AUTOSAR XML (schema 4-3-0)
package /MICROSAR/Dcm_swc
  5 x mode declaration group, all with category=EXPLICIT_ORDER:
    DcmControlDtcSetting: initial-mode=ENABLEDTCSETTING, on-transition-value=2
      mode ENABLEDTCSETTING: value=0
      mode DISABLEDTCSETTING: value=1
    DcmEcuReset: initial-mode=NONE, on-transition-value=7
      7 x mode:
        NONE: value=0
        HARD: value=1
        KEYONOFF: value=2
        SOFT: value=3
        JUMPTOBOOTLOADER: value=4
        JUMPTOSYSSUPPLIERBOOTLOADER: value=5
        EXECUTE: value=6
    DcmCommunicationControl: initial-mode=DCM_ENABLE_RX_TX_NORM, on-transition-value=12
      12 x mode:
        DCM_ENABLE_RX_TX_NORM: value=0
        DCM_ENABLE_RX_DISABLE_TX_NORM: value=1
        DCM_DISABLE_RX_ENABLE_TX_NORM: value=2
        DCM_DISABLE_RX_TX_NORMAL: value=3
        DCM_ENABLE_RX_TX_NM: value=4
        DCM_ENABLE_RX_DISABLE_TX_NM: value=5
        DCM_DISABLE_RX_ENABLE_TX_NM: value=6
        DCM_DISABLE_RX_TX_NM: value=7
        DCM_ENABLE_RX_TX_NORM_NM: value=8
        DCM_ENABLE_RX_DISABLE_TX_NORM_NM: value=9
        DCM_DISABLE_RX_ENABLE_TX_NORM_NM: value=10
        DCM_DISABLE_RX_TX_NORM_NM: value=11
    DcmResponseOnEvent: initial-mode=EVENT_CLEARED, on-transition-value=3
      mode EVENT_STARTED: value=0
      mode EVENT_STOPPED: value=1
      mode EVENT_CLEARED: value=2
    DcmDiagnosticSessionControl: initial-mode=DEFAULT_SESSION, on-transition-value=255
      9 x mode:
        DEFAULT_SESSION: value=1
        PROGRAMMING_SESSION: value=2
        EXTENDED_SESSION: value=3
        CODING_SESSION: value=65
        RSU_SESSION: value=68
        DEVELOPMENT_SESSION: value=79
        GarageMode: value=95
        SYSTEM_SUPPLIER_SPECIFIC_61: value=97
        DcmDspSessionRow_NXTRMFG: value=126
  data type mapping set DcmMappingSet  # Contains mapping for ModeDeclarationGroups which are provided by Dcm.
    mode-request-type-maps:
      implementation-data-type=Dcm_ControlDtcSettingType, mode-group=DcmControlDtcSetting
      implementation-data-type=Dcm_EcuResetType, mode-group=DcmEcuReset
      implementation-data-type=Dcm_DiagnosticSessionControlType, mode-group=DcmDiagnosticSessionControl
      implementation-data-type=Dcm_CommunicationModeType, mode-group=DcmCommunicationControl
      implementation-data-type=Dcm_ResponseOnEventType, mode-group=DcmResponseOnEvent
package /MICROSAR/Dcm_swc/DataTypes
  38 x impl type:
    Dcm_ConfirmationStatusType: compu {0=DCM_RES_POS_OK, 1=DCM_RES_POS_NOT_OK, 2=DCM_RES_NEG_OK, 3=DCM_RES_NEG_NOT_OK}, implementation-data-type=uint8
    Dcm_OpStatusType: compu {0=DCM_INITIAL, 1=DCM_PENDING, 2=DCM_CANCEL, 3=DCM_FORCE_RCRRP_OK, 64=DCM_FORCE_RCRRP_NOT_OK}, implementation-data-type=uint8
    Dcm_NegativeResponseCodeType: compu {0=DCM_E_POSITIVERESPONSE, 16=DCM_E_GENERALREJECT, 17=DCM_E_SERVICENOTSUPPORTED, 18=DCM_E_SUBFUNCTIONNOTSUPPORTED, 19=DCM_E_INCORRECTMESSAGELENGTHORINVALIDFORMAT, 20=DCM_E_RESPONSETOOLONG, 33=DCM_E_BUSYREPEATREQUEST, 34=DCM_E_CONDITIONSNOTCORRECT, 36=DCM_E_REQUESTSEQUENCEERROR, 37=DCM_E_NORESPONSEFROMSUBNETCOMPONENT, 38=DCM_E_FAILUREPREVENTSEXECUTIONOFREQUESTEDACTION, 49=DCM_E_REQUESTOUTOFRANGE, 51=DCM_E_SECURITYACCESSDENIED, 53=DCM_E_INVALIDKEY, 54=DCM_E_EXCEEDNUMBEROFATTEMPTS, 55=DCM_E_REQUIREDTIMEDELAYNOTEXPIRED, 112=DCM_E_UPLOADDOWNLOADNOTACCEPTED, 113=DCM_E_TRANSFERDATASUSPENDED, 114=DCM_E_GENERALPROGRAMMINGFAILURE, 115=DCM_E_WRONGBLOCKSEQUENCECOUNTER, 120=DCM_E_REQUESTCORRECTLYRECEIVEDRESPONSEPENDING, 126=DCM_E_SUBFUNCTIONNOTSUPPORTEDINACTIVESESSION, 127=DCM_E_SERVICENOTSUPPORTEDINACTIVESESSION, 129=DCM_E_RPMTOOHIGH, 130=DCM_E_RPMTOOLOW, 131=DCM_E_ENGINEISRUNNING, 132=DCM_E_ENGINEISNOTRUNNING, 133=DCM_E_ENGINERUNTIMETOOLOW, 134=DCM_E_TEMPERATURETOOHIGH, 135=DCM_E_TEMPERATURETOOLOW, 136=DCM_E_VEHICLESPEEDTOOHIGH, 137=DCM_E_VEHICLESPEEDTOOLOW, 138=DCM_E_THROTTLE_PEDALTOOHIGH, 139=DCM_E_THROTTLE_PEDALTOOLOW, 140=DCM_E_TRANSMISSIONRANGENOTINNEUTRAL, 141=DCM_E_TRANSMISSIONRANGENOTINGEAR, 143=DCM_E_BRAKESWITCH_NOTCLOSED, 144=DCM_E_SHIFTERLEVERNOTINPARK, 145=DCM_E_TORQUECONVERTERCLUTCHLOCKED, 146=DCM_E_VOLTAGETOOHIGH, 147=DCM_E_VOLTAGETOOLOW, 240..249=DCM_E_VMSCNC_0..DCM_E_VMSCNC_9, 250=DCM_E_VMSCNC_A, 251=DCM_E_VMSCNC_B, 252=DCM_E_VMSCNC_C, 253=DCM_E_VMSCNC_D, 254=DCM_E_VMSCNC_E}, implementation-data-type=uint8
    Dcm_ProtocolType: compu {0=DCM_OBD_ON_CAN, 1=DCM_OBD_ON_FLEXRAY, 2=DCM_OBD_ON_IP, 3=DCM_UDS_ON_CAN, 4=DCM_UDS_ON_FLEXRAY, 5=DCM_UDS_ON_IP, 12=DCM_NO_ACTIVE_PROTOCOL, 240..254=DCM_SUPPLIER_1..DCM_SUPPLIER_15}, implementation-data-type=uint8
    Dcm_RequestKindType: compu {0=DCM_REQ_KIND_NONE, 1=DCM_REQ_KIND_EXTERNAL, 2=DCM_REQ_KIND_ROE}, implementation-data-type=uint8
    Dcm_SecLevelType: compu {0=DCM_SEC_LEV_LOCKED, 1=DCM_SEC_LEV_L1}, implementation-data-type=uint8
    Dcm_SesCtrlType: compu {1=DCM_DEFAULT_SESSION, 2=DCM_PROGRAMMING_SESSION, 3=DCM_EXTENDED_DIAGNOSTIC_SESSION, 65=DCM_CODING_SESSION, 68=DCM_RSU_SESSION, 79=DCM_DEVELOPMENT_SESSION, 95=DCM_GarageMode, 97=DCM_SYSTEM_SUPPLIER_SPECIFIC_61, 126=DCM_DcmDspSessionRow_NXTRMFG}, implementation-data-type=uint8
    Dem_DTCFormatType: compu {0=DEM_DTC_FORMAT_OBD, 1=DEM_DTC_FORMAT_UDS, 2=DEM_DTC_FORMAT_J1939}, implementation-data-type=uint8
    Dem_DTCKindType: compu {1=DEM_DTC_KIND_ALL_DTCS, 2=DEM_DTC_KIND_EMISSION_REL_DTCS}, implementation-data-type=uint8
    Dem_DTCGroupType: range raw 0..16777215, implementation-data-type=uint32
    Dem_DTCOriginType: compu {1=DEM_DTC_ORIGIN_PRIMARY_MEMORY, 2=DEM_DTC_ORIGIN_MIRROR_MEMORY, 3=DEM_DTC_ORIGIN_PERMANENT_MEMORY, 4=DEM_DTC_ORIGIN_SECONDARY_MEMORY}, implementation-data-type=uint8
    Dcm_ControlDtcSettingType: compu {0=DCM_ENUM_ENABLEDTCSETTING, 1=DCM_ENUM_DISABLEDTCSETTING}, implementation-data-type=uint8
    Dcm_EcuResetType: compu {0=DCM_ENUM_NONE, 1=DCM_ENUM_HARD, 2=DCM_ENUM_KEYONOFF, 3=DCM_ENUM_SOFT, 4=DCM_ENUM_JUMPTOBOOTLOADER, 5=DCM_ENUM_JUMPTOSYSSUPPLIERBOOTLOADER, 6=DCM_ENUM_EXECUTE}, implementation-data-type=uint8
    Dcm_CommunicationModeType: compu {0=DCM_ENABLE_RX_TX_NORM, 1=DCM_ENABLE_RX_DISABLE_TX_NORM, 2=DCM_DISABLE_RX_ENABLE_TX_NORM, 3=DCM_DISABLE_RX_TX_NORMAL, 4=DCM_ENABLE_RX_TX_NM, 5=DCM_ENABLE_RX_DISABLE_TX_NM, 6=DCM_DISABLE_RX_ENABLE_TX_NM, 7=DCM_DISABLE_RX_TX_NM, 8=DCM_ENABLE_RX_TX_NORM_NM, 9=DCM_ENABLE_RX_DISABLE_TX_NORM_NM, 10=DCM_DISABLE_RX_ENABLE_TX_NORM_NM, 11=DCM_DISABLE_RX_TX_NORM_NM}, implementation-data-type=uint8
    Dcm_ResponseOnEventType: compu {0=DCM_ENUM_EVENT_STARTED, 1=DCM_ENUM_EVENT_STOPPED, 2=DCM_ENUM_EVENT_CLEARED}, implementation-data-type=uint8
    Dcm_Data4ByteType: category=ARRAY, sw-calibration-access=READ-ONLY
      element Dcm_Data4ByteTypeElement: array-size=4, array-size-semantics=FIXED-SIZE, implementation-data-type=uint8
    Dcm_Data8ByteType: category=ARRAY, sw-calibration-access=READ-ONLY
      element Dcm_Data8ByteTypeElement: array-size=8, array-size-semantics=FIXED-SIZE, implementation-data-type=uint8
    Dcm_Data132ByteType: category=ARRAY, sw-calibration-access=READ-ONLY
      element Dcm_Data132ByteTypeElement: array-size=132, array-size-semantics=FIXED-SIZE, implementation-data-type=uint8
    Dcm_Data256ByteType: category=ARRAY, sw-calibration-access=READ-ONLY
      element Dcm_Data256ByteTypeElement: array-size=256, array-size-semantics=FIXED-SIZE, implementation-data-type=uint8
    Dcm_Data1024ByteType: category=ARRAY, sw-calibration-access=READ-ONLY
      element Dcm_Data1024ByteTypeElement: array-size=1024, array-size-semantics=FIXED-SIZE, implementation-data-type=uint8
    Dcm_Data6ByteType: category=ARRAY, sw-calibration-access=READ-ONLY
      element Dcm_Data6ByteTypeElement: array-size=6, array-size-semantics=FIXED-SIZE, implementation-data-type=uint8
    Dcm_Data18ByteType: category=ARRAY, sw-calibration-access=READ-ONLY
      element Dcm_Data18ByteTypeElement: array-size=18, array-size-semantics=FIXED-SIZE, implementation-data-type=uint8
    Dcm_Data2ByteType: category=ARRAY, sw-calibration-access=READ-ONLY
      element Dcm_Data2ByteTypeElement: array-size=2, array-size-semantics=FIXED-SIZE, implementation-data-type=uint8
    Dcm_Data57ByteType: category=ARRAY, sw-calibration-access=READ-ONLY
      element Dcm_Data57ByteTypeElement: array-size=57, array-size-semantics=FIXED-SIZE, implementation-data-type=uint8
    Dcm_Data17ByteType: category=ARRAY, sw-calibration-access=READ-ONLY
      element Dcm_Data17ByteTypeElement: array-size=17, array-size-semantics=FIXED-SIZE, implementation-data-type=uint8
    Dcm_Data1ByteType: category=ARRAY, sw-calibration-access=READ-ONLY
      element Dcm_Data1ByteTypeElement: array-size=1, array-size-semantics=FIXED-SIZE, implementation-data-type=uint8
    Dcm_Data12ByteType: category=ARRAY, sw-calibration-access=READ-ONLY
      element Dcm_Data12ByteTypeElement: array-size=12, array-size-semantics=FIXED-SIZE, implementation-data-type=uint8
    Dcm_Data3ByteType: category=ARRAY, sw-calibration-access=READ-ONLY
      element Dcm_Data3ByteTypeElement: array-size=3, array-size-semantics=FIXED-SIZE, implementation-data-type=uint8
    Dcm_Data20ByteType: category=ARRAY, sw-calibration-access=READ-ONLY
      element Dcm_Data20ByteTypeElement: array-size=20, array-size-semantics=FIXED-SIZE, implementation-data-type=uint8
    Dcm_Data15ByteType: category=ARRAY, sw-calibration-access=READ-ONLY
      element Dcm_Data15ByteTypeElement: array-size=15, array-size-semantics=FIXED-SIZE, implementation-data-type=uint8
    Dcm_Data7ByteType: category=ARRAY, sw-calibration-access=READ-ONLY
      element Dcm_Data7ByteTypeElement: array-size=7, array-size-semantics=FIXED-SIZE, implementation-data-type=uint8
    Dcm_Data10ByteType: category=ARRAY, sw-calibration-access=READ-ONLY
      element Dcm_Data10ByteTypeElement: array-size=10, array-size-semantics=FIXED-SIZE, implementation-data-type=uint8
    Dcm_Data100ByteType: category=ARRAY, sw-calibration-access=READ-ONLY
      element Dcm_Data100ByteTypeElement: array-size=100, array-size-semantics=FIXED-SIZE, implementation-data-type=uint8
    Dcm_Data8195ByteType: category=ARRAY, sw-calibration-access=READ-ONLY
      element Dcm_Data8195ByteTypeElement: array-size=8195, array-size-semantics=FIXED-SIZE, implementation-data-type=uint8
    Dcm_Data9ByteType: category=ARRAY, sw-calibration-access=READ-ONLY
      element Dcm_Data9ByteTypeElement: array-size=9, array-size-semantics=FIXED-SIZE, implementation-data-type=uint8
    Dcm_DiagnosticSessionControlType: compu {1=DCM_ENUM_DEFAULT_SESSION, 2=DCM_ENUM_PROGRAMMING_SESSION, 3=DCM_ENUM_EXTENDED_SESSION, 65=DCM_ENUM_CODING_SESSION, 68=DCM_ENUM_RSU_SESSION, 79=DCM_ENUM_DEVELOPMENT_SESSION, 95=DCM_ENUM_GarageMode, 97=DCM_ENUM_SYSTEM_SUPPLIER_SPECIFIC_61, 126=DCM_ENUM_DcmDspSessionRow_NXTRMFG}, implementation-data-type=uint8
    Dcm_Data40ByteType: category=ARRAY, sw-calibration-access=READ-ONLY
      element Dcm_Data40ByteTypeElement: array-size=40, array-size-semantics=FIXED-SIZE, implementation-data-type=uint8
    Dcm_Data48ByteType: category=ARRAY, sw-calibration-access=READ-ONLY
      element Dcm_Data48ByteTypeElement: array-size=48, array-size-semantics=FIXED-SIZE, implementation-data-type=uint8
package /MICROSAR/Dcm_swc/Interfaces
  5 x mode switch interface, all with is-service=true, service-kind=DIAGNOSTIC-COMMUNICATION-MANAGER:
    DcmControlDtcSetting
      mode group DcmControlDtcSetting: type=DcmControlDtcSetting
    DcmEcuReset
      mode group DcmEcuReset: type=DcmEcuReset
    DcmDiagnosticSessionControl
      mode group DcmDiagnosticSessionControl: type=DcmDiagnosticSessionControl
    DcmCommunicationControl_ComMConf_ComMChannel_A_FlexRay_372befd6
      mode group DcmCommunicationControl_ComMConf_ComMChannel_A_FlexRay_372befd6: type=DcmCommunicationControl
    DcmResponseOnEvent_DcmDspRoeEvent
      mode group DcmResponseOnEvent_DcmDspRoeEvent: type=DcmResponseOnEvent
  62 x client server interface, all with is-service=true, service-kind=DIAGNOSTIC-COMMUNICATION-MANAGER:
    DCMServices
      6 x operation:
        GetActiveProtocol: possible-error=E_OK
          arg ActiveProtocol: type=Dcm_ProtocolType, direction=OUT
        GetSesCtrlType: possible-error=E_OK
          arg SesCtrlType: type=Dcm_SesCtrlType, direction=OUT
        ResetToDefaultSession: possible-error=E_OK
        GetSecurityLevel: possible-error=E_OK
          arg SecLevel: type=Dcm_SecLevelType, direction=OUT
        SetActiveDiagnostic: possible-error=E_OK
          arg active: type=boolean, direction=IN
        GetRequestKind: possible-error=DCMServices/E_NOT_OK
          arg TesterSourceAddress: type=uint16, direction=IN
          arg RequestKind: type=Dcm_RequestKindType, direction=OUT
      error E_OK: error-code=0
      error E_NOT_OK: error-code=1
    DCM_Roe
      operation TriggerOnEvent: possible-error=DCM_Roe/E_NOT_OK
      error E_NOT_OK: error-code=1
    SecurityAccess_DcmDspSecurityRow_Coding
      operation GetSeed: possible-error=[SecurityAccess_DcmDspSecurityRow_Coding/E_NOT_OK, SecurityAccess_DcmDspSecurityRow_Coding/DCM_E_PENDING]
        4 x arg:
          SecurityAccessDataRecord: type=Dcm_Data4ByteType, direction=IN
          OpStatus: type=Dcm_OpStatusType, direction=IN
          Seed: type=Dcm_Data8ByteType, direction=OUT
          ErrorCode: type=Dcm_NegativeResponseCodeType, direction=OUT
      operation CompareKey: possible-error=[SecurityAccess_DcmDspSecurityRow_Coding/E_NOT_OK, SecurityAccess_DcmDspSecurityRow_Coding/DCM_E_PENDING, DCM_E_COMPARE_KEY_FAILED]
        arg Key: type=Dcm_Data132ByteType, direction=IN
        arg OpStatus: type=Dcm_OpStatusType, direction=IN
        arg ErrorCode: type=Dcm_NegativeResponseCodeType, direction=OUT
      error E_NOT_OK: error-code=1
      error DCM_E_PENDING: error-code=10
      error DCM_E_COMPARE_KEY_FAILED: error-code=11
    RoutineServices_RcCm_Routine
      operation Start: possible-error=[RoutineServices_RcCm_Routine/E_NOT_OK, RoutineServices_RcCm_Routine/DCM_E_PENDING, RoutineServices_RcCm_Routine/DCM_E_FORCE_RCRRP]
        4 x arg:
          RcCmIcvRcoStruct_In: type=uint8, direction=IN
          OpStatus: type=Dcm_OpStatusType, direction=IN
          StatRoutineStatus_Out: type=uint8, direction=OUT
          ErrorCode: type=Dcm_NegativeResponseCodeType, direction=OUT
      error E_NOT_OK: error-code=1
      error DCM_E_PENDING: error-code=10
      error DCM_E_FORCE_RCRRP: error-code=12
    RoutineServices_RcCppc_Routine
      operation Start: possible-error=[RoutineServices_RcCppc_Routine/E_NOT_OK, RoutineServices_RcCppc_Routine/DCM_E_PENDING, RoutineServices_RcCppc_Routine/DCM_E_FORCE_RCRRP]
        4 x arg:
          OpStatus: type=Dcm_OpStatusType, direction=IN
          dataOut_Out: type=Dcm_Data256ByteType, direction=OUT
          DataLength: type=uint16, direction=OUT
          ErrorCode: type=Dcm_NegativeResponseCodeType, direction=OUT
      error E_NOT_OK: error-code=1
      error DCM_E_PENDING: error-code=10
      error DCM_E_FORCE_RCRRP: error-code=12
    RoutineServices_RcRswedi_Routine
      operation Start: possible-error=[RoutineServices_RcRswedi_Routine/E_NOT_OK, RoutineServices_RcRswedi_Routine/DCM_E_PENDING, RoutineServices_RcRswedi_Routine/DCM_E_FORCE_RCRRP]
        5 x arg:
          DataIn_In: type=Dcm_Data8ByteType, direction=IN
          OpStatus: type=Dcm_OpStatusType, direction=IN
          DataOut_Out: type=Dcm_Data256ByteType, direction=OUT
          DataLength: type=uint16, direction=OUT
          ErrorCode: type=Dcm_NegativeResponseCodeType, direction=OUT
      error E_NOT_OK: error-code=1
      error DCM_E_PENDING: error-code=10
      error DCM_E_FORCE_RCRRP: error-code=12
    RoutineServices_DeleteSwPackage_Routine
      operation Start: possible-error=[RoutineServices_DeleteSwPackage_Routine/E_NOT_OK, RoutineServices_DeleteSwPackage_Routine/DCM_E_PENDING, RoutineServices_DeleteSwPackage_Routine/DCM_E_FORCE_RCRRP]
        arg OpStatus: type=Dcm_OpStatusType, direction=IN
        arg ErrorCode: type=Dcm_NegativeResponseCodeType, direction=OUT
      error E_NOT_OK: error-code=1
      error DCM_E_PENDING: error-code=10
      error DCM_E_FORCE_RCRRP: error-code=12
    RoutineServices_DiagCommLoopback_Routine
      operation Start: possible-error=[RoutineServices_DiagCommLoopback_Routine/E_NOT_OK, RoutineServices_DiagCommLoopback_Routine/DCM_E_PENDING, RoutineServices_DiagCommLoopback_Routine/DCM_E_FORCE_RCRRP]
        5 x arg:
          dataIn_In: type=Dcm_Data1024ByteType, direction=IN
          OpStatus: type=Dcm_OpStatusType, direction=IN
          dataOut_Out: type=Dcm_Data1024ByteType, direction=OUT
          DataLength: type=uint16, direction=INOUT
          ErrorCode: type=Dcm_NegativeResponseCodeType, direction=OUT
      error E_NOT_OK: error-code=1
      error DCM_E_PENDING: error-code=10
      error DCM_E_FORCE_RCRRP: error-code=12
    RoutineServices_DmClientTriggerDtcEntry_Routine
      operation Start: possible-error=[RoutineServices_DmClientTriggerDtcEntry_Routine/E_NOT_OK, RoutineServices_DmClientTriggerDtcEntry_Routine/DCM_E_PENDING, RoutineServices_DmClientTriggerDtcEntry_Routine/DCM_E_FORCE_RCRRP]
        7 x arg:
          DTCType_In: type=uint8, direction=IN
          OpStatus: type=Dcm_OpStatusType, direction=IN
          DTCTypeOut_Out: type=uint8, direction=OUT
          DTCByte{1..3}_Out: type=uint8, direction=OUT
          ErrorCode: type=Dcm_NegativeResponseCodeType, direction=OUT
      error E_NOT_OK: error-code=1
      error DCM_E_PENDING: error-code=10
      error DCM_E_FORCE_RCRRP: error-code=12
    RoutineServices_IsLoeschen_Routine
      operation Start: possible-error=[RoutineServices_IsLoeschen_Routine/E_NOT_OK, RoutineServices_IsLoeschen_Routine/DCM_E_PENDING, RoutineServices_IsLoeschen_Routine/DCM_E_FORCE_RCRRP]
        arg OpStatus: type=Dcm_OpStatusType, direction=IN
        arg ErrorCode: type=Dcm_NegativeResponseCodeType, direction=OUT
      error E_NOT_OK: error-code=1
      error DCM_E_PENDING: error-code=10
      error DCM_E_FORCE_RCRRP: error-code=12
    RoutineServices_Energiesparmode_Routine
      operation Start: possible-error=[RoutineServices_Energiesparmode_Routine/E_NOT_OK, RoutineServices_Energiesparmode_Routine/DCM_E_PENDING, RoutineServices_Energiesparmode_Routine/DCM_E_FORCE_RCRRP]
        arg dataIn_In: type=uint8, direction=IN
        arg OpStatus: type=Dcm_OpStatusType, direction=IN
        arg ErrorCode: type=Dcm_NegativeResponseCodeType, direction=OUT
      error E_NOT_OK: error-code=1
      error DCM_E_PENDING: error-code=10
      error DCM_E_FORCE_RCRRP: error-code=12
    RoutineServices_ControlExtendedEnergySavingState_Routine
      operation Start: possible-error=[RoutineServices_ControlExtendedEnergySavingState_Routine/E_NOT_OK, RoutineServices_ControlExtendedEnergySavingState_Routine/DCM_E_PENDING, RoutineServices_ControlExtendedEnergySavingState_Routine/DCM_E_FORCE_RCRRP]
        arg dataIn_In: type=uint8, direction=IN
        arg OpStatus: type=Dcm_OpStatusType, direction=IN
        arg ErrorCode: type=Dcm_NegativeResponseCodeType, direction=OUT
      error E_NOT_OK: error-code=1
      error DCM_E_PENDING: error-code=10
      error DCM_E_FORCE_RCRRP: error-code=12
    RoutineServices_ReadNcd_Routine
      operation Start: possible-error=[RoutineServices_ReadNcd_Routine/E_NOT_OK, RoutineServices_ReadNcd_Routine/DCM_E_PENDING, RoutineServices_ReadNcd_Routine/DCM_E_FORCE_RCRRP]
        5 x arg:
          ArgCodingArea_In: type=Dcm_Data6ByteType, direction=IN
          OpStatus: type=Dcm_OpStatusType, direction=IN
          StatCodingArea_Out: type=Dcm_Data1024ByteType, direction=OUT
          DataLength: type=uint16, direction=OUT
          ErrorCode: type=Dcm_NegativeResponseCodeType, direction=OUT
      error E_NOT_OK: error-code=1
      error DCM_E_PENDING: error-code=10
      error DCM_E_FORCE_RCRRP: error-code=12
    RoutineServices_WriteNcd_Routine
      operation Start: possible-error=[RoutineServices_WriteNcd_Routine/E_NOT_OK, RoutineServices_WriteNcd_Routine/DCM_E_PENDING, RoutineServices_WriteNcd_Routine/DCM_E_FORCE_RCRRP]
        4 x arg:
          ArgCodingArea_In: type=Dcm_Data1024ByteType, direction=IN
          OpStatus: type=Dcm_OpStatusType, direction=IN
          DataLength: type=uint16, direction=IN
          ErrorCode: type=Dcm_NegativeResponseCodeType, direction=OUT
      error E_NOT_OK: error-code=1
      error DCM_E_PENDING: error-code=10
      error DCM_E_FORCE_RCRRP: error-code=12
    RoutineServices_CheckNcd_Routine
      operation Start: possible-error=[RoutineServices_CheckNcd_Routine/E_NOT_OK, RoutineServices_CheckNcd_Routine/DCM_E_PENDING, RoutineServices_CheckNcd_Routine/DCM_E_FORCE_RCRRP]
        5 x arg:
          Cps_In: type=Dcm_Data18ByteType, direction=IN
          OpStatus: type=Dcm_OpStatusType, direction=IN
          StatCheckNcdResult_Out: type=uint8, direction=OUT
          DataLength: type=uint16, direction=IN
          ErrorCode: type=Dcm_NegativeResponseCodeType, direction=OUT
      error E_NOT_OK: error-code=1
      error DCM_E_PENDING: error-code=10
      error DCM_E_FORCE_RCRRP: error-code=12
    RoutineServices_DarhStrtStop_Routine
      operation Start: possible-error=[RoutineServices_DarhStrtStop_Routine/E_NOT_OK, RoutineServices_DarhStrtStop_Routine/DCM_E_PENDING, RoutineServices_DarhStrtStop_Routine/DCM_E_FORCE_RCRRP]
        arg OpStatus: type=Dcm_OpStatusType, direction=IN
        arg ErrorCode: type=Dcm_NegativeResponseCodeType, direction=OUT
      operation Stop: possible-error=[RoutineServices_DarhStrtStop_Routine/E_NOT_OK, RoutineServices_DarhStrtStop_Routine/DCM_E_PENDING, RoutineServices_DarhStrtStop_Routine/DCM_E_FORCE_RCRRP]
        arg OpStatus: type=Dcm_OpStatusType, direction=IN
        arg ErrorCode: type=Dcm_NegativeResponseCodeType, direction=OUT
      error E_NOT_OK: error-code=1
      error DCM_E_PENDING: error-code=10
      error DCM_E_FORCE_RCRRP: error-code=12
    RoutineServices_SteuernEpsPulldriftOffsetReset_Routine
      operation Start: possible-error=[RoutineServices_SteuernEpsPulldriftOffsetReset_Routine/E_NOT_OK, RoutineServices_SteuernEpsPulldriftOffsetReset_Routine/DCM_E_PENDING, RoutineServices_SteuernEpsPulldriftOffsetReset_Routine/DCM_E_FORCE_RCRRP]
        arg OpStatus: type=Dcm_OpStatusType, direction=IN
        arg ErrorCode: type=Dcm_NegativeResponseCodeType, direction=OUT
      error E_NOT_OK: error-code=1
      error DCM_E_PENDING: error-code=10
      error DCM_E_FORCE_RCRRP: error-code=12
    RoutineServices_EpsPendeln_Routine
      operation Start: possible-error=[RoutineServices_EpsPendeln_Routine/E_NOT_OK, RoutineServices_EpsPendeln_Routine/DCM_E_PENDING, RoutineServices_EpsPendeln_Routine/DCM_E_FORCE_RCRRP]
        5 x arg:
          Frequenz_In: type=uint8, direction=IN
          MaxAmplitude_In: type=uint8, direction=IN
          NumberOfCycles_In: type=uint8, direction=IN
          OpStatus: type=Dcm_OpStatusType, direction=IN
          ErrorCode: type=Dcm_NegativeResponseCodeType, direction=OUT
      operation RequestResults: possible-error=[RoutineServices_EpsPendeln_Routine/E_NOT_OK, RoutineServices_EpsPendeln_Routine/DCM_E_PENDING, RoutineServices_EpsPendeln_Routine/DCM_E_FORCE_RCRRP]
        arg OpStatus: type=Dcm_OpStatusType, direction=IN
        arg StatEpsPendelnAktivNr_Out: type=uint8, direction=OUT
        arg ErrorCode: type=Dcm_NegativeResponseCodeType, direction=OUT
      error E_NOT_OK: error-code=1
      error DCM_E_PENDING: error-code=10
      error DCM_E_FORCE_RCRRP: error-code=12
    RoutineServices_EpsLenkwinkelsensorKalibrierungReset_Routine
      operation Start: possible-error=[RoutineServices_EpsLenkwinkelsensorKalibrierungReset_Routine/E_NOT_OK, RoutineServices_EpsLenkwinkelsensorKalibrierungReset_Routine/DCM_E_PENDING, RoutineServices_EpsLenkwinkelsensorKalibrierungReset_Routine/DCM_E_FORCE_RCRRP]
        arg OpStatus: type=Dcm_OpStatusType, direction=IN
        arg ErrorCode: type=Dcm_NegativeResponseCodeType, direction=OUT
      error E_NOT_OK: error-code=1
      error DCM_E_PENDING: error-code=10
      error DCM_E_FORCE_RCRRP: error-code=12
    RoutineServices_EpsInitialisierungService_Routine
      operation Start: possible-error=[RoutineServices_EpsInitialisierungService_Routine/E_NOT_OK, RoutineServices_EpsInitialisierungService_Routine/DCM_E_PENDING, RoutineServices_EpsInitialisierungService_Routine/DCM_E_FORCE_RCRRP]
        arg OpStatus: type=Dcm_OpStatusType, direction=IN
        arg ErrorCode: type=Dcm_NegativeResponseCodeType, direction=OUT
      operation Stop: possible-error=[RoutineServices_EpsInitialisierungService_Routine/E_NOT_OK, RoutineServices_EpsInitialisierungService_Routine/DCM_E_PENDING, RoutineServices_EpsInitialisierungService_Routine/DCM_E_FORCE_RCRRP]
        arg OpStatus: type=Dcm_OpStatusType, direction=IN
        arg ErrorCode: type=Dcm_NegativeResponseCodeType, direction=OUT
      operation RequestResults: possible-error=[RoutineServices_EpsInitialisierungService_Routine/E_NOT_OK, RoutineServices_EpsInitialisierungService_Routine/DCM_E_PENDING, RoutineServices_EpsInitialisierungService_Routine/DCM_E_FORCE_RCRRP]
        5 x arg:
          OpStatus: type=Dcm_OpStatusType, direction=IN
          StatRoutineStatus_Out: type=uint8, direction=OUT
          StatLenkradwinkelWert_Out: type=Dcm_Data2ByteType, direction=OUT
          StatSensorZustandNr_Out: type=uint8, direction=OUT
          ErrorCode: type=Dcm_NegativeResponseCodeType, direction=OUT
      error E_NOT_OK: error-code=1
      error DCM_E_PENDING: error-code=10
      error DCM_E_FORCE_RCRRP: error-code=12
    RoutineServices_EpsVerfahren_Routine
      operation Start: possible-error=[RoutineServices_EpsVerfahren_Routine/E_NOT_OK, RoutineServices_EpsVerfahren_Routine/DCM_E_PENDING, RoutineServices_EpsVerfahren_Routine/DCM_E_FORCE_RCRRP]
        6 x arg:
          Winkel_In: type=Dcm_Data2ByteType, direction=IN
          Winkelgeschwindigkeit_In: type=uint8, direction=IN
          Winkelbeschleunigung_In: type=uint8, direction=IN
          AbsolutEin_In: type=uint8, direction=IN
          OpStatus: type=Dcm_OpStatusType, direction=IN
          ErrorCode: type=Dcm_NegativeResponseCodeType, direction=OUT
      operation RequestResults: possible-error=[RoutineServices_EpsVerfahren_Routine/E_NOT_OK, RoutineServices_EpsVerfahren_Routine/DCM_E_PENDING, RoutineServices_EpsVerfahren_Routine/DCM_E_FORCE_RCRRP]
        arg OpStatus: type=Dcm_OpStatusType, direction=IN
        arg StatEpsVerfahrenAktivNr_Out: type=uint8, direction=OUT
        arg ErrorCode: type=Dcm_NegativeResponseCodeType, direction=OUT
      error E_NOT_OK: error-code=1
      error DCM_E_PENDING: error-code=10
      error DCM_E_FORCE_RCRRP: error-code=12
    RoutineServices_EpsInitialisierungWerk_Routine
      operation Start: possible-error=[RoutineServices_EpsInitialisierungWerk_Routine/E_NOT_OK, RoutineServices_EpsInitialisierungWerk_Routine/DCM_E_PENDING, RoutineServices_EpsInitialisierungWerk_Routine/DCM_E_FORCE_RCRRP]
        5 x arg:
          Winkel_In: type=uint8, direction=IN
          Winkelgeschwindigkeit_In: type=uint8, direction=IN
          Winkelbeschleunigung_In: type=uint8, direction=IN
          OpStatus: type=Dcm_OpStatusType, direction=IN
          ErrorCode: type=Dcm_NegativeResponseCodeType, direction=OUT
      operation Stop: possible-error=[RoutineServices_EpsInitialisierungWerk_Routine/E_NOT_OK, RoutineServices_EpsInitialisierungWerk_Routine/DCM_E_PENDING, RoutineServices_EpsInitialisierungWerk_Routine/DCM_E_FORCE_RCRRP]
        arg OpStatus: type=Dcm_OpStatusType, direction=IN
        arg ErrorCode: type=Dcm_NegativeResponseCodeType, direction=OUT
      operation RequestResults: possible-error=[RoutineServices_EpsInitialisierungWerk_Routine/E_NOT_OK, RoutineServices_EpsInitialisierungWerk_Routine/DCM_E_PENDING, RoutineServices_EpsInitialisierungWerk_Routine/DCM_E_FORCE_RCRRP]
        arg OpStatus: type=Dcm_OpStatusType, direction=IN
        arg StatRoutineStatus_Out: type=uint8, direction=OUT
        arg ErrorCode: type=Dcm_NegativeResponseCodeType, direction=OUT
      error E_NOT_OK: error-code=1
      error DCM_E_PENDING: error-code=10
      error DCM_E_FORCE_RCRRP: error-code=12
    RoutineServices_EpsZahnstangenmitteReset_Routine
      operation Start: possible-error=[RoutineServices_EpsZahnstangenmitteReset_Routine/E_NOT_OK, RoutineServices_EpsZahnstangenmitteReset_Routine/DCM_E_PENDING, RoutineServices_EpsZahnstangenmitteReset_Routine/DCM_E_FORCE_RCRRP]
        arg OpStatus: type=Dcm_OpStatusType, direction=IN
        arg ErrorCode: type=Dcm_NegativeResponseCodeType, direction=OUT
      error E_NOT_OK: error-code=1
      error DCM_E_PENDING: error-code=10
      error DCM_E_FORCE_RCRRP: error-code=12
    RoutineServices_SteuernEpsMultiturnwertReset_Routine
      operation Start: possible-error=[RoutineServices_SteuernEpsMultiturnwertReset_Routine/E_NOT_OK, RoutineServices_SteuernEpsMultiturnwertReset_Routine/DCM_E_PENDING, RoutineServices_SteuernEpsMultiturnwertReset_Routine/DCM_E_FORCE_RCRRP]
        arg OpStatus: type=Dcm_OpStatusType, direction=IN
        arg ErrorCode: type=Dcm_NegativeResponseCodeType, direction=OUT
      error E_NOT_OK: error-code=1
      error DCM_E_PENDING: error-code=10
      error DCM_E_FORCE_RCRRP: error-code=12
    RoutineServices_RcEm_Routine
      operation Start: possible-error=[RoutineServices_RcEm_Routine/E_NOT_OK, RoutineServices_RcEm_Routine/DCM_E_PENDING, RoutineServices_RcEm_Routine/DCM_E_FORCE_RCRRP]
        4 x arg:
          RcEmIeRco_In: type=uint8, direction=IN
          OpStatus: type=Dcm_OpStatusType, direction=IN
          StatRoutineStatus_Out: type=uint8, direction=OUT
          ErrorCode: type=Dcm_NegativeResponseCodeType, direction=OUT
      error E_NOT_OK: error-code=1
      error DCM_E_PENDING: error-code=10
      error DCM_E_FORCE_RCRRP: error-code=12
    RoutineServices_RcCpd_Routine
      operation Start: possible-error=[RoutineServices_RcCpd_Routine/E_NOT_OK, RoutineServices_RcCpd_Routine/DCM_E_PENDING, RoutineServices_RcCpd_Routine/DCM_E_FORCE_RCRRP]
        arg OpStatus: type=Dcm_OpStatusType, direction=IN
        arg StatRoutineStatus_Out: type=uint8, direction=OUT
        arg ErrorCode: type=Dcm_NegativeResponseCodeType, direction=OUT
      error E_NOT_OK: error-code=1
      error DCM_E_PENDING: error-code=10
      error DCM_E_FORCE_RCRRP: error-code=12
    DataServices_DcmDspData_SvkBackup0
      operation ReadData: possible-error=[DataServices_DcmDspData_SvkBackup0/E_NOT_OK, DataServices_DcmDspData_SvkBackup0/DCM_E_PENDING]
        arg OpStatus: type=Dcm_OpStatusType, direction=IN
        arg Data: type=Dcm_Data57ByteType, direction=OUT
      operation ConditionCheckRead: possible-error=[DataServices_DcmDspData_SvkBackup0/E_NOT_OK, DataServices_DcmDspData_SvkBackup0/DCM_E_PENDING]
        arg OpStatus: type=Dcm_OpStatusType, direction=IN
        arg ErrorCode: type=Dcm_NegativeResponseCodeType, direction=OUT
      error E_NOT_OK: error-code=1
      error DCM_E_PENDING: error-code=10
    DataServices_DcmDspData_SvkBackup1
      operation ReadData: possible-error=[DataServices_DcmDspData_SvkBackup1/E_NOT_OK, DataServices_DcmDspData_SvkBackup1/DCM_E_PENDING]
        arg OpStatus: type=Dcm_OpStatusType, direction=IN
        arg Data: type=Dcm_Data57ByteType, direction=OUT
      operation ConditionCheckRead: possible-error=[DataServices_DcmDspData_SvkBackup1/E_NOT_OK, DataServices_DcmDspData_SvkBackup1/DCM_E_PENDING]
        arg OpStatus: type=Dcm_OpStatusType, direction=IN
        arg ErrorCode: type=Dcm_NegativeResponseCodeType, direction=OUT
      error E_NOT_OK: error-code=1
      error DCM_E_PENDING: error-code=10
    DataServices_DcmDspData_SvkBackup2
      operation ReadData: possible-error=[DataServices_DcmDspData_SvkBackup2/E_NOT_OK, DataServices_DcmDspData_SvkBackup2/DCM_E_PENDING]
        arg OpStatus: type=Dcm_OpStatusType, direction=IN
        arg Data: type=Dcm_Data57ByteType, direction=OUT
      operation ConditionCheckRead: possible-error=[DataServices_DcmDspData_SvkBackup2/E_NOT_OK, DataServices_DcmDspData_SvkBackup2/DCM_E_PENDING]
        arg OpStatus: type=Dcm_OpStatusType, direction=IN
        arg ErrorCode: type=Dcm_NegativeResponseCodeType, direction=OUT
      error E_NOT_OK: error-code=1
      error DCM_E_PENDING: error-code=10
    DataServices_DcmDspData_Vin
      operation ReadData: possible-error=[DataServices_DcmDspData_Vin/E_NOT_OK, DataServices_DcmDspData_Vin/DCM_E_PENDING]
        arg OpStatus: type=Dcm_OpStatusType, direction=IN
        arg Data: type=Dcm_Data17ByteType, direction=OUT
      error E_NOT_OK: error-code=1
      error DCM_E_PENDING: error-code=10
    DataServices_DID_1704_DmDtcAktiveMeldung
      operation ReadData: possible-error=[DataServices_DID_1704_DmDtcAktiveMeldung/E_NOT_OK, DataServices_DID_1704_DmDtcAktiveMeldung/DCM_E_PENDING]
        arg OpStatus: type=Dcm_OpStatusType, direction=IN
        arg Data: type=Dcm_Data4ByteType, direction=OUT
      operation ConditionCheckRead: possible-error=[DataServices_DID_1704_DmDtcAktiveMeldung/E_NOT_OK, DataServices_DID_1704_DmDtcAktiveMeldung/DCM_E_PENDING]
        arg OpStatus: type=Dcm_OpStatusType, direction=IN
        arg ErrorCode: type=Dcm_NegativeResponseCodeType, direction=OUT
      error E_NOT_OK: error-code=1
      error DCM_E_PENDING: error-code=10
    DataServices_DID_37FF_ReadProtocolData
      operation ReadData: possible-error=DataServices_DID_37FF_ReadProtocolData/E_NOT_OK
        arg Data: type=Dcm_Data9ByteType, direction=OUT
      operation ConditionCheckRead: possible-error=DataServices_DID_37FF_ReadProtocolData/E_NOT_OK
        arg ErrorCode: type=Dcm_NegativeResponseCodeType, direction=OUT
      error E_NOT_OK: error-code=1
    DataServices_DID_F18C_EcuSerialNumber
      operation ReadData: possible-error=DataServices_DID_F18C_EcuSerialNumber/E_NOT_OK
        arg Data: type=Dcm_Data10ByteType, direction=OUT
      error E_NOT_OK: error-code=1
    DataServices_DID_2540_MileKmEeprom
      operation ReadData: possible-error=[DataServices_DID_2540_MileKmEeprom/E_NOT_OK, DataServices_DID_2540_MileKmEeprom/DCM_E_PENDING]
        arg OpStatus: type=Dcm_OpStatusType, direction=IN
        arg Data: type=Dcm_Data3ByteType, direction=OUT
      operation ConditionCheckRead: possible-error=[DataServices_DID_2540_MileKmEeprom/E_NOT_OK, DataServices_DID_2540_MileKmEeprom/DCM_E_PENDING]
        arg OpStatus: type=Dcm_OpStatusType, direction=IN
        arg ErrorCode: type=Dcm_NegativeResponseCodeType, direction=OUT
      error E_NOT_OK: error-code=1
      error DCM_E_PENDING: error-code=10
    DataServices_DID_F101_SvkAktuell
      operation ReadData: possible-error=[DataServices_DID_F101_SvkAktuell/E_NOT_OK, DataServices_DID_F101_SvkAktuell/DCM_E_PENDING]
        arg OpStatus: type=Dcm_OpStatusType, direction=IN
        arg Data: type=Dcm_Data100ByteType, direction=OUT
      operation ConditionCheckRead: possible-error=[DataServices_DID_F101_SvkAktuell/E_NOT_OK, DataServices_DID_F101_SvkAktuell/DCM_E_PENDING]
        arg OpStatus: type=Dcm_OpStatusType, direction=IN
        arg ErrorCode: type=Dcm_NegativeResponseCodeType, direction=OUT
      error E_NOT_OK: error-code=1
      error DCM_E_PENDING: error-code=10
    DataServices_DID_1701_Systemzeit
      operation ReadData: possible-error=DataServices_DID_1701_Systemzeit/E_NOT_OK
        arg Data: type=Dcm_Data4ByteType, direction=OUT
      error E_NOT_OK: error-code=1
    DataServices_DID_1723_DmIsDtcActiveResponse
      operation ReadData: possible-error=DataServices_DID_1723_DmIsDtcActiveResponse/E_NOT_OK
        arg Data: type=Dcm_Data40ByteType, direction=OUT
      operation ReadDataLength: possible-error=DataServices_DID_1723_DmIsDtcActiveResponse/E_NOT_OK
        arg DataLength: type=uint16, direction=OUT
      error E_NOT_OK: error-code=1
    DataServices_DID_100E_ExtendedEnergySavingState
      operation ReadData: possible-error=DataServices_DID_100E_ExtendedEnergySavingState/E_NOT_OK
        arg Data: type=Dcm_Data1ByteType, direction=OUT
      error E_NOT_OK: error-code=1
    DataServices_DID_2504_FlashTimingParameter
      operation ReadData: possible-error=DataServices_DID_2504_FlashTimingParameter/E_NOT_OK
        arg Data: type=Dcm_Data12ByteType, direction=OUT
      error E_NOT_OK: error-code=1
    DataServices_DID_DB99_EpsMomentensensor
      operation ReadData: possible-error=[DataServices_DID_DB99_EpsMomentensensor/E_NOT_OK, DataServices_DID_DB99_EpsMomentensensor/DCM_E_PENDING]
        arg OpStatus: type=Dcm_OpStatusType, direction=IN
        arg Data: type=Dcm_Data3ByteType, direction=OUT
      operation ConditionCheckRead: possible-error=[DataServices_DID_DB99_EpsMomentensensor/E_NOT_OK, DataServices_DID_DB99_EpsMomentensensor/DCM_E_PENDING]
        arg OpStatus: type=Dcm_OpStatusType, direction=IN
        arg ErrorCode: type=Dcm_NegativeResponseCodeType, direction=OUT
      error E_NOT_OK: error-code=1
      error DCM_E_PENDING: error-code=10
    DataServices_DID_DB5A_EpsLenkwinkelsensorKalibrierung
      operation ReadData: possible-error=[DataServices_DID_DB5A_EpsLenkwinkelsensorKalibrierung/E_NOT_OK, DataServices_DID_DB5A_EpsLenkwinkelsensorKalibrierung/DCM_E_PENDING]
        arg OpStatus: type=Dcm_OpStatusType, direction=IN
        arg Data: type=Dcm_Data2ByteType, direction=OUT
      operation ConditionCheckRead: possible-error=[DataServices_DID_DB5A_EpsLenkwinkelsensorKalibrierung/E_NOT_OK, DataServices_DID_DB5A_EpsLenkwinkelsensorKalibrierung/DCM_E_PENDING]
        arg OpStatus: type=Dcm_OpStatusType, direction=IN
        arg ErrorCode: type=Dcm_NegativeResponseCodeType, direction=OUT
      operation WriteData: possible-error=[DataServices_DID_DB5A_EpsLenkwinkelsensorKalibrierung/E_NOT_OK, DataServices_DID_DB5A_EpsLenkwinkelsensorKalibrierung/DCM_E_PENDING]
        arg Data: type=Dcm_Data2ByteType, direction=IN
        arg OpStatus: type=Dcm_OpStatusType, direction=IN
        arg ErrorCode: type=Dcm_NegativeResponseCodeType, direction=OUT
      error E_NOT_OK: error-code=1
      error DCM_E_PENDING: error-code=10
    DataServices_DID_1000_Pruefstempel
      operation ReadData: possible-error=[DataServices_DID_1000_Pruefstempel/E_NOT_OK, DataServices_DID_1000_Pruefstempel/DCM_E_PENDING]
        arg OpStatus: type=Dcm_OpStatusType, direction=IN
        arg Data: type=Dcm_Data3ByteType, direction=OUT
      operation ConditionCheckRead: possible-error=[DataServices_DID_1000_Pruefstempel/E_NOT_OK, DataServices_DID_1000_Pruefstempel/DCM_E_PENDING]
        arg OpStatus: type=Dcm_OpStatusType, direction=IN
        arg ErrorCode: type=Dcm_NegativeResponseCodeType, direction=OUT
      operation WriteData: possible-error=[DataServices_DID_1000_Pruefstempel/E_NOT_OK, DataServices_DID_1000_Pruefstempel/DCM_E_PENDING]
        arg Data: type=Dcm_Data3ByteType, direction=IN
        arg OpStatus: type=Dcm_OpStatusType, direction=IN
        arg ErrorCode: type=Dcm_NegativeResponseCodeType, direction=OUT
      error E_NOT_OK: error-code=1
      error DCM_E_PENDING: error-code=10
    DataServices_DID_F18A_SystemSupplierIdentifier
      operation ReadData: possible-error=[DataServices_DID_F18A_SystemSupplierIdentifier/E_NOT_OK, DataServices_DID_F18A_SystemSupplierIdentifier/DCM_E_PENDING]
        arg OpStatus: type=Dcm_OpStatusType, direction=IN
        arg Data: type=Dcm_Data3ByteType, direction=OUT
      operation ConditionCheckRead: possible-error=[DataServices_DID_F18A_SystemSupplierIdentifier/E_NOT_OK, DataServices_DID_F18A_SystemSupplierIdentifier/DCM_E_PENDING]
        arg OpStatus: type=Dcm_OpStatusType, direction=IN
        arg ErrorCode: type=Dcm_NegativeResponseCodeType, direction=OUT
      error E_NOT_OK: error-code=1
      error DCM_E_PENDING: error-code=10
    DataServices_DID_100A_EnergySavingState
      operation ReadData: possible-error=DataServices_DID_100A_EnergySavingState/E_NOT_OK
        arg Data: type=Dcm_Data1ByteType, direction=OUT
      error E_NOT_OK: error-code=1
    DataServices_DID_DB57_EpsRitzelwinkelsensor
      operation ReadData: possible-error=[DataServices_DID_DB57_EpsRitzelwinkelsensor/E_NOT_OK, DataServices_DID_DB57_EpsRitzelwinkelsensor/DCM_E_PENDING]
        arg OpStatus: type=Dcm_OpStatusType, direction=IN
        arg Data: type=Dcm_Data7ByteType, direction=OUT
      operation ConditionCheckRead: possible-error=[DataServices_DID_DB57_EpsRitzelwinkelsensor/E_NOT_OK, DataServices_DID_DB57_EpsRitzelwinkelsensor/DCM_E_PENDING]
        arg OpStatus: type=Dcm_OpStatusType, direction=IN
        arg ErrorCode: type=Dcm_NegativeResponseCodeType, direction=OUT
      error E_NOT_OK: error-code=1
      error DCM_E_PENDING: error-code=10
    DataServices_DID_F150_SgbdIdx
      operation ReadData: possible-error=DataServices_DID_F150_SgbdIdx/E_NOT_OK
        arg Data: type=Dcm_Data3ByteType, direction=OUT
      error E_NOT_OK: error-code=1
    DataServices_DID_DB3C_StatusFzgBordnetz
      operation ReadData: possible-error=[DataServices_DID_DB3C_StatusFzgBordnetz/E_NOT_OK, DataServices_DID_DB3C_StatusFzgBordnetz/DCM_E_PENDING]
        arg OpStatus: type=Dcm_OpStatusType, direction=IN
        arg Data: type=Dcm_Data15ByteType, direction=OUT
      operation ConditionCheckRead: possible-error=[DataServices_DID_DB3C_StatusFzgBordnetz/E_NOT_OK, DataServices_DID_DB3C_StatusFzgBordnetz/DCM_E_PENDING]
        arg OpStatus: type=Dcm_OpStatusType, direction=IN
        arg ErrorCode: type=Dcm_NegativeResponseCodeType, direction=OUT
      error E_NOT_OK: error-code=1
      error DCM_E_PENDING: error-code=10
    DataServices_DID_F152_Readhwmodificationindex
      operation ReadData: possible-error=DataServices_DID_F152_Readhwmodificationindex/E_NOT_OK
        arg Data: type=Dcm_Data2ByteType, direction=OUT
      error E_NOT_OK: error-code=1
    DataServices_DID_F15A_WdbiFp
      operation WriteData: possible-error=[DataServices_DID_F15A_WdbiFp/E_NOT_OK, DataServices_DID_F15A_WdbiFp/DCM_E_PENDING]
        arg Data: type=Dcm_Data1ByteType, direction=IN
        arg OpStatus: type=Dcm_OpStatusType, direction=IN
        arg ErrorCode: type=Dcm_NegativeResponseCodeType, direction=OUT
      error E_NOT_OK: error-code=1
      error DCM_E_PENDING: error-code=10
    DataServices_DID_DFDD_GelernterZahnstangenweg
      operation ReadData: possible-error=[DataServices_DID_DFDD_GelernterZahnstangenweg/E_NOT_OK, DataServices_DID_DFDD_GelernterZahnstangenweg/DCM_E_PENDING]
        arg OpStatus: type=Dcm_OpStatusType, direction=IN
        arg Data: type=Dcm_Data8ByteType, direction=OUT
      operation ConditionCheckRead: possible-error=[DataServices_DID_DFDD_GelernterZahnstangenweg/E_NOT_OK, DataServices_DID_DFDD_GelernterZahnstangenweg/DCM_E_PENDING]
        arg OpStatus: type=Dcm_OpStatusType, direction=IN
        arg ErrorCode: type=Dcm_NegativeResponseCodeType, direction=OUT
      error E_NOT_OK: error-code=1
      error DCM_E_PENDING: error-code=10
    DataServices_DID_2507_SwfkDeleteSupported
      operation ReadData: possible-error=DataServices_DID_2507_SwfkDeleteSupported/E_NOT_OK
        arg Data: type=Dcm_Data1ByteType, direction=OUT
      operation ConditionCheckRead: possible-error=DataServices_DID_2507_SwfkDeleteSupported/E_NOT_OK
        arg ErrorCode: type=Dcm_NegativeResponseCodeType, direction=OUT
      error E_NOT_OK: error-code=1
    DataServices_DID_F100_ReadActiveSessionState
      operation ReadData: possible-error=DataServices_DID_F100_ReadActiveSessionState/E_NOT_OK
        arg Data: type=Dcm_Data4ByteType, direction=OUT
      operation ConditionCheckRead: possible-error=DataServices_DID_F100_ReadActiveSessionState/E_NOT_OK
        arg ErrorCode: type=Dcm_NegativeResponseCodeType, direction=OUT
      error E_NOT_OK: error-code=1
    DataServices_DID_250B_ReadSwRevision
      operation ReadData: possible-error=[DataServices_DID_250B_ReadSwRevision/E_NOT_OK, DataServices_DID_250B_ReadSwRevision/DCM_E_PENDING]
        arg OpStatus: type=Dcm_OpStatusType, direction=IN
        arg Data: type=Dcm_Data140ByteType, direction=OUT
      operation ConditionCheckRead: possible-error=[DataServices_DID_250B_ReadSwRevision/E_NOT_OK, DataServices_DID_250B_ReadSwRevision/DCM_E_PENDING]
        arg OpStatus: type=Dcm_OpStatusType, direction=IN
        arg ErrorCode: type=Dcm_NegativeResponseCodeType, direction=OUT
      error E_NOT_OK: error-code=1
      error DCM_E_PENDING: error-code=10
    DataServices_DID_F102_SvkSysSupplier
      operation ReadData: possible-error=[DataServices_DID_F102_SvkSysSupplier/E_NOT_OK, DataServices_DID_F102_SvkSysSupplier/DCM_E_PENDING]
        arg OpStatus: type=Dcm_OpStatusType, direction=IN
        arg Data: type=Dcm_Data48ByteType, direction=OUT
      operation ConditionCheckRead: possible-error=[DataServices_DID_F102_SvkSysSupplier/E_NOT_OK, DataServices_DID_F102_SvkSysSupplier/DCM_E_PENDING]
        arg OpStatus: type=Dcm_OpStatusType, direction=IN
        arg ErrorCode: type=Dcm_NegativeResponseCodeType, direction=OUT
      error E_NOT_OK: error-code=1
      error DCM_E_PENDING: error-code=10
    DataServices_DID_2541_StatusCalcvn
      operation ReadData: possible-error=DataServices_DID_2541_StatusCalcvn/E_NOT_OK
        arg Data: type=Dcm_Data20ByteType, direction=OUT
      error E_NOT_OK: error-code=1
    DataServices_DID_DC77_EpsZahnstangenmitte
      operation ReadData: possible-error=[DataServices_DID_DC77_EpsZahnstangenmitte/E_NOT_OK, DataServices_DID_DC77_EpsZahnstangenmitte/DCM_E_PENDING]
        arg OpStatus: type=Dcm_OpStatusType, direction=IN
        arg Data: type=Dcm_Data1ByteType, direction=OUT
      operation ConditionCheckRead: possible-error=[DataServices_DID_DC77_EpsZahnstangenmitte/E_NOT_OK, DataServices_DID_DC77_EpsZahnstangenmitte/DCM_E_PENDING]
        arg OpStatus: type=Dcm_OpStatusType, direction=IN
        arg ErrorCode: type=Dcm_NegativeResponseCodeType, direction=OUT
      error E_NOT_OK: error-code=1
      error DCM_E_PENDING: error-code=10
    DataServices_DID_F103_SvkWerk
      operation ReadData: possible-error=[DataServices_DID_F103_SvkWerk/E_NOT_OK, DataServices_DID_F103_SvkWerk/DCM_E_PENDING]
        arg OpStatus: type=Dcm_OpStatusType, direction=IN
        arg Data: type=Dcm_Data48ByteType, direction=OUT
      operation ConditionCheckRead: possible-error=[DataServices_DID_F103_SvkWerk/E_NOT_OK, DataServices_DID_F103_SvkWerk/DCM_E_PENDING]
        arg OpStatus: type=Dcm_OpStatusType, direction=IN
        arg ErrorCode: type=Dcm_NegativeResponseCodeType, direction=OUT
      error E_NOT_OK: error-code=1
      error DCM_E_PENDING: error-code=10
    DataServices_DID_2503_ProgrammingCounterMaxValue
      operation ReadData: possible-error=DataServices_DID_2503_ProgrammingCounterMaxValue/E_NOT_OK
        arg Data: type=Dcm_Data2ByteType, direction=OUT
      operation ConditionCheckRead: possible-error=DataServices_DID_2503_ProgrammingCounterMaxValue/E_NOT_OK
        arg ErrorCode: type=Dcm_NegativeResponseCodeType, direction=OUT
      operation WriteData: possible-error=DataServices_DID_2503_ProgrammingCounterMaxValue/E_NOT_OK
        arg Data: type=Dcm_Data2ByteType, direction=IN
        arg ErrorCode: type=Dcm_NegativeResponseCodeType, direction=OUT
      error E_NOT_OK: error-code=1
    DataServices_DID_F18B_Herstelldatum
      operation ReadData: possible-error=DataServices_DID_F18B_Herstelldatum/E_NOT_OK
        arg Data: type=Dcm_Data3ByteType, direction=OUT
      error E_NOT_OK: error-code=1
    ServiceRequestNotification
      operation Indication: possible-error=[ServiceRequestNotification/E_NOT_OK, E_REQUEST_NOT_ACCEPTED]
        6 x arg:
          SID: type=uint8, direction=IN
          RequestData: type=Dcm_Data8195ByteType, direction=IN
          DataSize: type=uint16, direction=IN
          ReqType: type=uint8, direction=IN
          SourceAddress: type=uint16, direction=IN
          ErrorCode: type=Dcm_NegativeResponseCodeType, direction=OUT
      operation Confirmation: possible-error=ServiceRequestNotification/E_NOT_OK
        4 x arg, all with direction=IN:
          SID: type=uint8
          ReqType: type=uint8
          SourceAddress: type=uint16
          ConfirmationStatus: type=Dcm_ConfirmationStatusType
      error E_NOT_OK: error-code=1
      error E_REQUEST_NOT_ACCEPTED: error-code=8
    DataServices_DID_37FE_Cps
      operation ReadData: possible-error=DataServices_DID_37FE_Cps/E_NOT_OK
        arg Data: type=Dcm_Data18ByteType, direction=OUT
      operation ConditionCheckRead: possible-error=DataServices_DID_37FE_Cps/E_NOT_OK
        arg ErrorCode: type=Dcm_NegativeResponseCodeType, direction=OUT
      error E_NOT_OK: error-code=1
    DataServices_DID_2502_ProgrammingCounter
      operation ReadData: possible-error=DataServices_DID_2502_ProgrammingCounter/E_NOT_OK
        arg Data: type=Dcm_Data4ByteType, direction=OUT
      error E_NOT_OK: error-code=1
package /MICROSAR/Dcm_swc/ComponentTypes
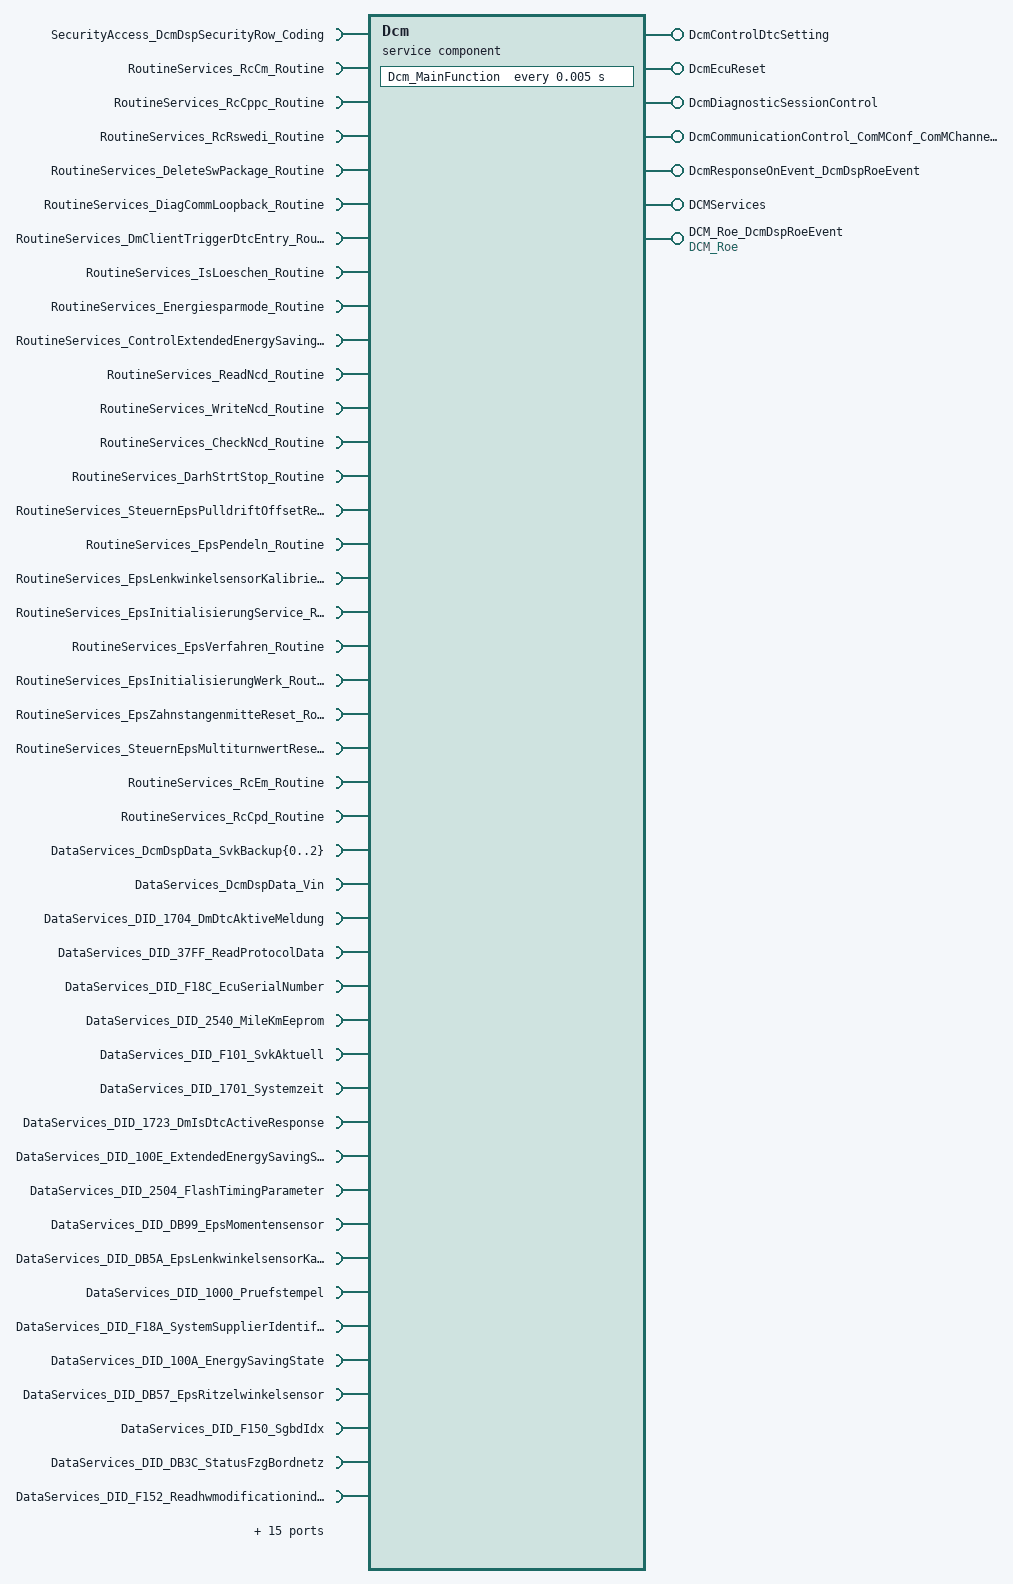
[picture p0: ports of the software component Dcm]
  service sw component type Dcm: category=SERVICE_COMPONENT
    7 x provide port:
      DcmControlDtcSetting: provided-interface=DcmControlDtcSetting
      DcmEcuReset: mode-switch-sender-com-spec{mode-group=DcmEcuReset, mode-switched-ack=timeout=0}, provided-interface=DcmEcuReset
      DcmDiagnosticSessionControl: provided-interface=DcmDiagnosticSessionControl
      DcmCommunicationControl_ComMConf_ComMChannel_A_FlexRay_372befd6: provided-interface=DcmCommunicationControl_ComMConf_ComMChannel_A_FlexRay_372befd6
      DcmResponseOnEvent_DcmDspRoeEvent: provided-interface=DcmResponseOnEvent_DcmDspRoeEvent
      DCMServices: provided-interface=DCMServices
      DCM_Roe_DcmDspRoeEvent: provided-interface=DCM_Roe
    61 x require port:
      SecurityAccess_DcmDspSecurityRow_Coding: required-interface=SecurityAccess_DcmDspSecurityRow_Coding
      RoutineServices_RcCm_Routine: required-interface=RoutineServices_RcCm_Routine
      RoutineServices_RcCppc_Routine: required-interface=RoutineServices_RcCppc_Routine
      RoutineServices_RcRswedi_Routine: required-interface=RoutineServices_RcRswedi_Routine
      RoutineServices_DeleteSwPackage_Routine: required-interface=RoutineServices_DeleteSwPackage_Routine
      RoutineServices_DiagCommLoopback_Routine: required-interface=RoutineServices_DiagCommLoopback_Routine
      RoutineServices_DmClientTriggerDtcEntry_Routine: required-interface=RoutineServices_DmClientTriggerDtcEntry_Routine
      RoutineServices_IsLoeschen_Routine: required-interface=RoutineServices_IsLoeschen_Routine
      RoutineServices_Energiesparmode_Routine: required-interface=RoutineServices_Energiesparmode_Routine
      RoutineServices_ControlExtendedEnergySavingState_Routine: required-interface=RoutineServices_ControlExtendedEnergySavingState_Routine
      RoutineServices_ReadNcd_Routine: required-interface=RoutineServices_ReadNcd_Routine
      RoutineServices_WriteNcd_Routine: required-interface=RoutineServices_WriteNcd_Routine
      RoutineServices_CheckNcd_Routine: required-interface=RoutineServices_CheckNcd_Routine
      RoutineServices_DarhStrtStop_Routine: required-interface=RoutineServices_DarhStrtStop_Routine
      RoutineServices_SteuernEpsPulldriftOffsetReset_Routine: required-interface=RoutineServices_SteuernEpsPulldriftOffsetReset_Routine
      RoutineServices_EpsPendeln_Routine: required-interface=RoutineServices_EpsPendeln_Routine
      RoutineServices_EpsLenkwinkelsensorKalibrierungReset_Routine: required-interface=RoutineServices_EpsLenkwinkelsensorKalibrierungReset_Routine
      RoutineServices_EpsInitialisierungService_Routine: required-interface=RoutineServices_EpsInitialisierungService_Routine
      RoutineServices_EpsVerfahren_Routine: required-interface=RoutineServices_EpsVerfahren_Routine
      RoutineServices_EpsInitialisierungWerk_Routine: required-interface=RoutineServices_EpsInitialisierungWerk_Routine
      RoutineServices_EpsZahnstangenmitteReset_Routine: required-interface=RoutineServices_EpsZahnstangenmitteReset_Routine
      RoutineServices_SteuernEpsMultiturnwertReset_Routine: required-interface=RoutineServices_SteuernEpsMultiturnwertReset_Routine
      RoutineServices_RcEm_Routine: required-interface=RoutineServices_RcEm_Routine
      RoutineServices_RcCpd_Routine: required-interface=RoutineServices_RcCpd_Routine
      DataServices_DcmDspData_SvkBackup{0..2}: required-interface=DataServices_DcmDspData_SvkBackup{0..2}
      DataServices_DcmDspData_Vin: required-interface=DataServices_DcmDspData_Vin
      DataServices_DID_1704_DmDtcAktiveMeldung: required-interface=DataServices_DID_1704_DmDtcAktiveMeldung
      DataServices_DID_37FF_ReadProtocolData: required-interface=DataServices_DID_37FF_ReadProtocolData
      DataServices_DID_F18C_EcuSerialNumber: required-interface=DataServices_DID_F18C_EcuSerialNumber
      DataServices_DID_2540_MileKmEeprom: required-interface=DataServices_DID_2540_MileKmEeprom
      DataServices_DID_F101_SvkAktuell: required-interface=DataServices_DID_F101_SvkAktuell
      DataServices_DID_1701_Systemzeit: required-interface=DataServices_DID_1701_Systemzeit
      DataServices_DID_1723_DmIsDtcActiveResponse: required-interface=DataServices_DID_1723_DmIsDtcActiveResponse
      DataServices_DID_100E_ExtendedEnergySavingState: required-interface=DataServices_DID_100E_ExtendedEnergySavingState
      DataServices_DID_2504_FlashTimingParameter: required-interface=DataServices_DID_2504_FlashTimingParameter
      DataServices_DID_DB99_EpsMomentensensor: required-interface=DataServices_DID_DB99_EpsMomentensensor
      DataServices_DID_DB5A_EpsLenkwinkelsensorKalibrierung: required-interface=DataServices_DID_DB5A_EpsLenkwinkelsensorKalibrierung
      DataServices_DID_1000_Pruefstempel: required-interface=DataServices_DID_1000_Pruefstempel
      DataServices_DID_F18A_SystemSupplierIdentifier: required-interface=DataServices_DID_F18A_SystemSupplierIdentifier
      DataServices_DID_100A_EnergySavingState: required-interface=DataServices_DID_100A_EnergySavingState
      DataServices_DID_DB57_EpsRitzelwinkelsensor: required-interface=DataServices_DID_DB57_EpsRitzelwinkelsensor
      DataServices_DID_F150_SgbdIdx: required-interface=DataServices_DID_F150_SgbdIdx
      DataServices_DID_DB3C_StatusFzgBordnetz: required-interface=DataServices_DID_DB3C_StatusFzgBordnetz
      DataServices_DID_F152_Readhwmodificationindex: required-interface=DataServices_DID_F152_Readhwmodificationindex
      DataServices_DID_F15A_WdbiFp: required-interface=DataServices_DID_F15A_WdbiFp
      DataServices_DID_DFDD_GelernterZahnstangenweg: required-interface=DataServices_DID_DFDD_GelernterZahnstangenweg
      DataServices_DID_2507_SwfkDeleteSupported: required-interface=DataServices_DID_2507_SwfkDeleteSupported
      DataServices_DID_F100_ReadActiveSessionState: required-interface=DataServices_DID_F100_ReadActiveSessionState
      DataServices_DID_250B_ReadSwRevision: required-interface=DataServices_DID_250B_ReadSwRevision
      DataServices_DID_F102_SvkSysSupplier: required-interface=DataServices_DID_F102_SvkSysSupplier
      DataServices_DID_2541_StatusCalcvn: required-interface=DataServices_DID_2541_StatusCalcvn
      DataServices_DID_DC77_EpsZahnstangenmitte: required-interface=DataServices_DID_DC77_EpsZahnstangenmitte
      DataServices_DID_F103_SvkWerk: required-interface=DataServices_DID_F103_SvkWerk
      DataServices_DID_2503_ProgrammingCounterMaxValue: required-interface=DataServices_DID_2503_ProgrammingCounterMaxValue
      DataServices_DID_F18B_Herstelldatum: required-interface=DataServices_DID_F18B_Herstelldatum
      ServiceRequestManufacturerNotification_StdDiag: required-interface=ServiceRequestNotification
      DataServices_DID_37FE_Cps: required-interface=DataServices_DID_37FE_Cps
      ServiceRequestManufacturerNotification_Coding: required-interface=ServiceRequestNotification
      DataServices_DID_2502_ProgrammingCounter: required-interface=DataServices_DID_2502_ProgrammingCounter
    behavior DcmInternalBehavior: data-type-mapping=DcmMappingSet, handle-termination-and-restart=NO-SUPPORT, included-data-type-set=data-type=[Dcm_ConfirmationStatusType, Dcm_OpStatusType, Dcm_NegativeResponseCodeType, Dcm_ProtocolType, Dcm_RequestKindType, Dcm_SecLevelType, Dcm_SesCtrlType, Dcm_ControlDtcSettingType, Dcm_EcuResetType, Dcm_DiagnosticSessionControlType, Dcm_CommunicationModeType, Dcm_ResponseOnEventType]
      7 x operation invoked event:
        OpEventGetActiveProtocol_GetActiveProtocol_DCMServices: start-on-event=GetActiveProtocol, operation=DCMServices.GetActiveProtocol
        OpEventGetSesCtrlType_GetSesCtrlType_DCMServices: start-on-event=GetSesCtrlType, operation=DCMServices.GetSesCtrlType
        OpEventResetToDefaultSession_ResetToDefaultSession_DCMServices: start-on-event=ResetToDefaultSession, operation=DCMServices.ResetToDefaultSession
        OpEventGetSecurityLevel_GetSecurityLevel_DCMServices: start-on-event=GetSecurityLevel, operation=DCMServices.GetSecurityLevel
        OpEventSetActiveDiagnostic_SetActiveDiagnostic_DCMServices: start-on-event=SetActiveDiagnostic, operation=DCMServices.SetActiveDiagnostic
        OpEventGetRequestKind_GetRequestKind_DCMServices: start-on-event=GetRequestKind, operation=DCMServices.GetRequestKind
        OpEventTriggerOnEvent_TriggerOnEvent_DCM_Roe_DcmDspRoeEvent: start-on-event=TriggerOnEvent, operation=DCM_Roe_DcmDspRoeEvent.TriggerOnEvent
      timing event Timer_Dcm_MainFunction: start-on-event=Dcm_MainFunction, period=0.005
      port-api-options:
        enable-take-address=true, indirect-api=false, port=DcmControlDtcSetting
        enable-take-address=true, indirect-api=false, port=DcmEcuReset
        enable-take-address=true, indirect-api=false, port=DcmDiagnosticSessionControl
        enable-take-address=true, indirect-api=false, port=DcmCommunicationControl_ComMConf_ComMChannel_A_FlexRay_372befd6
        enable-take-address=true, indirect-api=false, port=DcmResponseOnEvent_DcmDspRoeEvent
        enable-take-address=true, indirect-api=false, port=DCMServices
        {enable-take-address=true, indirect-api=false, port-defined-argument-value{value=0, value-type=uint8}, port=DCM_Roe_DcmDspRoeEvent}
        enable-take-address=true, indirect-api=false, port=ServiceRequestManufacturerNotification_StdDiag
        enable-take-address=true, indirect-api=false, port=SecurityAccess_DcmDspSecurityRow_Coding
        enable-take-address=true, indirect-api=false, port=RoutineServices_RcCm_Routine
        enable-take-address=true, indirect-api=false, port=RoutineServices_RcCppc_Routine
        enable-take-address=true, indirect-api=false, port=RoutineServices_RcRswedi_Routine
        enable-take-address=true, indirect-api=false, port=RoutineServices_DeleteSwPackage_Routine
        enable-take-address=true, indirect-api=false, port=RoutineServices_DiagCommLoopback_Routine
        enable-take-address=true, indirect-api=false, port=RoutineServices_DmClientTriggerDtcEntry_Routine
        enable-take-address=true, indirect-api=false, port=RoutineServices_IsLoeschen_Routine
        enable-take-address=true, indirect-api=false, port=RoutineServices_Energiesparmode_Routine
        enable-take-address=true, indirect-api=false, port=RoutineServices_ControlExtendedEnergySavingState_Routine
        enable-take-address=true, indirect-api=false, port=RoutineServices_ReadNcd_Routine
        enable-take-address=true, indirect-api=false, port=RoutineServices_WriteNcd_Routine
        enable-take-address=true, indirect-api=false, port=RoutineServices_CheckNcd_Routine
        enable-take-address=true, indirect-api=false, port=RoutineServices_DarhStrtStop_Routine
        enable-take-address=true, indirect-api=false, port=RoutineServices_SteuernEpsPulldriftOffsetReset_Routine
        enable-take-address=true, indirect-api=false, port=RoutineServices_EpsPendeln_Routine
        enable-take-address=true, indirect-api=false, port=RoutineServices_EpsLenkwinkelsensorKalibrierungReset_Routine
        enable-take-address=true, indirect-api=false, port=RoutineServices_EpsInitialisierungService_Routine
        enable-take-address=true, indirect-api=false, port=RoutineServices_EpsVerfahren_Routine
        enable-take-address=true, indirect-api=false, port=RoutineServices_EpsInitialisierungWerk_Routine
        enable-take-address=true, indirect-api=false, port=RoutineServices_EpsZahnstangenmitteReset_Routine
        enable-take-address=true, indirect-api=false, port=RoutineServices_SteuernEpsMultiturnwertReset_Routine
        enable-take-address=true, indirect-api=false, port=RoutineServices_RcEm_Routine
        enable-take-address=true, indirect-api=false, port=RoutineServices_RcCpd_Routine
        enable-take-address=true, indirect-api=false, port=DataServices_DcmDspData_SvkBackup{0..2}
        enable-take-address=true, indirect-api=false, port=DataServices_DcmDspData_Vin
        enable-take-address=true, indirect-api=false, port=DataServices_DID_1704_DmDtcAktiveMeldung
        enable-take-address=true, indirect-api=false, port=DataServices_DID_37FF_ReadProtocolData
        enable-take-address=true, indirect-api=false, port=DataServices_DID_F18C_EcuSerialNumber
        enable-take-address=true, indirect-api=false, port=DataServices_DID_2540_MileKmEeprom
        enable-take-address=true, indirect-api=false, port=DataServices_DID_F101_SvkAktuell
        enable-take-address=true, indirect-api=false, port=DataServices_DID_1701_Systemzeit
        enable-take-address=true, indirect-api=false, port=DataServices_DID_1723_DmIsDtcActiveResponse
        enable-take-address=true, indirect-api=false, port=DataServices_DID_100E_ExtendedEnergySavingState
        enable-take-address=true, indirect-api=false, port=DataServices_DID_2504_FlashTimingParameter
        enable-take-address=true, indirect-api=false, port=DataServices_DID_DB99_EpsMomentensensor
        enable-take-address=true, indirect-api=false, port=DataServices_DID_DB5A_EpsLenkwinkelsensorKalibrierung
        enable-take-address=true, indirect-api=false, port=DataServices_DID_1000_Pruefstempel
        enable-take-address=true, indirect-api=false, port=DataServices_DID_F18A_SystemSupplierIdentifier
        enable-take-address=true, indirect-api=false, port=DataServices_DID_100A_EnergySavingState
        enable-take-address=true, indirect-api=false, port=DataServices_DID_DB57_EpsRitzelwinkelsensor
        enable-take-address=true, indirect-api=false, port=DataServices_DID_F150_SgbdIdx
        enable-take-address=true, indirect-api=false, port=DataServices_DID_DB3C_StatusFzgBordnetz
        enable-take-address=true, indirect-api=false, port=DataServices_DID_F152_Readhwmodificationindex
        enable-take-address=true, indirect-api=false, port=DataServices_DID_F15A_WdbiFp
        enable-take-address=true, indirect-api=false, port=DataServices_DID_DFDD_GelernterZahnstangenweg
        enable-take-address=true, indirect-api=false, port=DataServices_DID_2507_SwfkDeleteSupported
        enable-take-address=true, indirect-api=false, port=DataServices_DID_F100_ReadActiveSessionState
        enable-take-address=true, indirect-api=false, port=DataServices_DID_250B_ReadSwRevision
        enable-take-address=true, indirect-api=false, port=DataServices_DID_F102_SvkSysSupplier
        enable-take-address=true, indirect-api=false, port=DataServices_DID_2541_StatusCalcvn
        enable-take-address=true, indirect-api=false, port=DataServices_DID_DC77_EpsZahnstangenmitte
        enable-take-address=true, indirect-api=false, port=DataServices_DID_F103_SvkWerk
        enable-take-address=true, indirect-api=false, port=DataServices_DID_2503_ProgrammingCounterMaxValue
        enable-take-address=true, indirect-api=false, port=DataServices_DID_F18B_Herstelldatum
        enable-take-address=true, indirect-api=false, port=DataServices_DID_37FE_Cps
        enable-take-address=true, indirect-api=false, port=ServiceRequestManufacturerNotification_Coding
        enable-take-address=true, indirect-api=false, port=DataServices_DID_2502_ProgrammingCounter
      8 x runnable:
        GetActiveProtocol: can-be-invoked-concurrently=true, symbol=Dcm_GetActiveProtocol
        GetSesCtrlType: can-be-invoked-concurrently=true, symbol=Dcm_GetSesCtrlType
        ResetToDefaultSession: can-be-invoked-concurrently=true, symbol=Dcm_ResetToDefaultSession
        GetSecurityLevel: can-be-invoked-concurrently=true, symbol=Dcm_GetSecurityLevel
        SetActiveDiagnostic: can-be-invoked-concurrently=true, symbol=Dcm_SetActiveDiagnostic
        GetRequestKind: can-be-invoked-concurrently=true, symbol=Dcm_GetRequestKind
        TriggerOnEvent: can-be-invoked-concurrently=true, symbol=Dcm_TriggerOnEvent
        Dcm_MainFunction
          5 x mode switch point:
            ModeSwitchPointDcm_MainFunction_DcmControlDtcSetting_DcmControlDtcSetting: mode-group=DcmControlDtcSetting.DcmControlDtcSetting
            ModeSwitchPointDcm_MainFunction_DcmEcuReset_DcmEcuReset: mode-group=DcmEcuReset.DcmEcuReset
            ModeSwitchPointDcm_MainFunction_DcmDiagnosticSessionControl_DcmDiagnosticSessionControl: mode-group=DcmDiagnosticSessionControl.DcmDiagnosticSessionControl
            ModeSwitchPointDcm_MainFunction_DcmCommunicationControl_ComMConf_ComMChannel_A_FlexRay_372befd6_DcmCommunicationControl_213d5a3c: mode-group=DcmCommunicationControl_ComMConf_ComMChannel_A_FlexRay_372befd6.DcmCommunicationControl_ComMConf_ComMChannel_A_FlexRay_372befd6
            ModeSwitchPointDcm_MainFunction_DcmResponseOnEvent_DcmDspRoeEvent_DcmResponseOnEvent_DcmDspRoeEvent: mode-group=DcmResponseOnEvent_DcmDspRoeEvent.DcmResponseOnEvent_DcmDspRoeEvent
          97 x sync call, all with timeout=0:
            OpServerCallDcm_MainFunction_Indication_ServiceRequestManufacturerNotification_StdDiag: operation=ServiceRequestManufacturerNotification_StdDiag.Indication
            OpServerCallDcm_MainFunction_Confirmation_ServiceRequestManufacturerNotification_StdDiag: operation=ServiceRequestManufacturerNotification_StdDiag.Confirmation
            OpServerCallDcm_MainFunction_Indication_ServiceRequestManufacturerNotification_Coding: operation=ServiceRequestManufacturerNotification_Coding.Indication
            OpServerCallDcm_MainFunction_Confirmation_ServiceRequestManufacturerNotification_Coding: operation=ServiceRequestManufacturerNotification_Coding.Confirmation
            OpServerCallDcm_MainFunction_GetSeed_SecurityAccess_DcmDspSecurityRow_Coding: operation=SecurityAccess_DcmDspSecurityRow_Coding.GetSeed
            OpServerCallDcm_MainFunction_CompareKey_SecurityAccess_DcmDspSecurityRow_Coding: operation=SecurityAccess_DcmDspSecurityRow_Coding.CompareKey
            OpServerCallDcm_MainFunction_Start_RoutineServices_RcCm_Routine: operation=RoutineServices_RcCm_Routine.Start
            OpServerCallDcm_MainFunction_Start_RoutineServices_RcCppc_Routine: operation=RoutineServices_RcCppc_Routine.Start
            OpServerCallDcm_MainFunction_Start_RoutineServices_RcRswedi_Routine: operation=RoutineServices_RcRswedi_Routine.Start
            OpServerCallDcm_MainFunction_Start_RoutineServices_DeleteSwPackage_Routine: operation=RoutineServices_DeleteSwPackage_Routine.Start
            OpServerCallDcm_MainFunction_Start_RoutineServices_DiagCommLoopback_Routine: operation=RoutineServices_DiagCommLoopback_Routine.Start
            OpServerCallDcm_MainFunction_Start_RoutineServices_DmClientTriggerDtcEntry_Routine: operation=RoutineServices_DmClientTriggerDtcEntry_Routine.Start
            OpServerCallDcm_MainFunction_Start_RoutineServices_IsLoeschen_Routine: operation=RoutineServices_IsLoeschen_Routine.Start
            OpServerCallDcm_MainFunction_Start_RoutineServices_Energiesparmode_Routine: operation=RoutineServices_Energiesparmode_Routine.Start
            OpServerCallDcm_MainFunction_Start_RoutineServices_ControlExtendedEnergySavingState_Routine: operation=RoutineServices_ControlExtendedEnergySavingState_Routine.Start
            OpServerCallDcm_MainFunction_Start_RoutineServices_ReadNcd_Routine: operation=RoutineServices_ReadNcd_Routine.Start
            OpServerCallDcm_MainFunction_Start_RoutineServices_WriteNcd_Routine: operation=RoutineServices_WriteNcd_Routine.Start
            OpServerCallDcm_MainFunction_Start_RoutineServices_CheckNcd_Routine: operation=RoutineServices_CheckNcd_Routine.Start
            OpServerCallDcm_MainFunction_Start_RoutineServices_DarhStrtStop_Routine: operation=RoutineServices_DarhStrtStop_Routine.Start
            OpServerCallDcm_MainFunction_Stop_RoutineServices_DarhStrtStop_Routine: operation=RoutineServices_DarhStrtStop_Routine.Stop
            OpServerCallDcm_MainFunction_Start_RoutineServices_SteuernEpsPulldriftOffsetReset_Routine: operation=RoutineServices_SteuernEpsPulldriftOffsetReset_Routine.Start
            OpServerCallDcm_MainFunction_Start_RoutineServices_EpsPendeln_Routine: operation=RoutineServices_EpsPendeln_Routine.Start
            OpServerCallDcm_MainFunction_RequestResults_RoutineServices_EpsPendeln_Routine: operation=RoutineServices_EpsPendeln_Routine.RequestResults
            OpServerCallDcm_MainFunction_Start_RoutineServices_EpsLenkwinkelsensorKalibrierungReset_Routine: operation=RoutineServices_EpsLenkwinkelsensorKalibrierungReset_Routine.Start
            OpServerCallDcm_MainFunction_Start_RoutineServices_EpsInitialisierungService_Routine: operation=RoutineServices_EpsInitialisierungService_Routine.Start
            OpServerCallDcm_MainFunction_Stop_RoutineServices_EpsInitialisierungService_Routine: operation=RoutineServices_EpsInitialisierungService_Routine.Stop
            OpServerCallDcm_MainFunction_RequestResults_RoutineServices_EpsInitialisierungService_Routine: operation=RoutineServices_EpsInitialisierungService_Routine.RequestResults
            OpServerCallDcm_MainFunction_Start_RoutineServices_EpsVerfahren_Routine: operation=RoutineServices_EpsVerfahren_Routine.Start
            OpServerCallDcm_MainFunction_RequestResults_RoutineServices_EpsVerfahren_Routine: operation=RoutineServices_EpsVerfahren_Routine.RequestResults
            OpServerCallDcm_MainFunction_Start_RoutineServices_EpsInitialisierungWerk_Routine: operation=RoutineServices_EpsInitialisierungWerk_Routine.Start
            OpServerCallDcm_MainFunction_Stop_RoutineServices_EpsInitialisierungWerk_Routine: operation=RoutineServices_EpsInitialisierungWerk_Routine.Stop
            OpServerCallDcm_MainFunction_RequestResults_RoutineServices_EpsInitialisierungWerk_Routine: operation=RoutineServices_EpsInitialisierungWerk_Routine.RequestResults
            OpServerCallDcm_MainFunction_Start_RoutineServices_EpsZahnstangenmitteReset_Routine: operation=RoutineServices_EpsZahnstangenmitteReset_Routine.Start
            OpServerCallDcm_MainFunction_Start_RoutineServices_SteuernEpsMultiturnwertReset_Routine: operation=RoutineServices_SteuernEpsMultiturnwertReset_Routine.Start
            OpServerCallDcm_MainFunction_Start_RoutineServices_RcEm_Routine: operation=RoutineServices_RcEm_Routine.Start
            OpServerCallDcm_MainFunction_Start_RoutineServices_RcCpd_Routine: operation=RoutineServices_RcCpd_Routine.Start
            OpServerCallDcm_MainFunction_ReadData_DataServices_DcmDspData_SvkBackup0: operation=DataServices_DcmDspData_SvkBackup0.ReadData
            OpServerCallDcm_MainFunction_ConditionCheckRead_DataServices_DcmDspData_SvkBackup0: operation=DataServices_DcmDspData_SvkBackup0.ConditionCheckRead
            OpServerCallDcm_MainFunction_ReadData_DataServices_DcmDspData_SvkBackup1: operation=DataServices_DcmDspData_SvkBackup1.ReadData
            OpServerCallDcm_MainFunction_ConditionCheckRead_DataServices_DcmDspData_SvkBackup1: operation=DataServices_DcmDspData_SvkBackup1.ConditionCheckRead
            OpServerCallDcm_MainFunction_ReadData_DataServices_DcmDspData_SvkBackup2: operation=DataServices_DcmDspData_SvkBackup2.ReadData
            OpServerCallDcm_MainFunction_ConditionCheckRead_DataServices_DcmDspData_SvkBackup2: operation=DataServices_DcmDspData_SvkBackup2.ConditionCheckRead
            OpServerCallDcm_MainFunction_ReadData_DataServices_DcmDspData_Vin: operation=DataServices_DcmDspData_Vin.ReadData
            OpServerCallDcm_MainFunction_ReadData_DataServices_DID_1704_DmDtcAktiveMeldung: operation=DataServices_DID_1704_DmDtcAktiveMeldung.ReadData
            OpServerCallDcm_MainFunction_ConditionCheckRead_DataServices_DID_1704_DmDtcAktiveMeldung: operation=DataServices_DID_1704_DmDtcAktiveMeldung.ConditionCheckRead
            OpServerCallDcm_MainFunction_ReadData_DataServices_DID_37FF_ReadProtocolData: operation=DataServices_DID_37FF_ReadProtocolData.ReadData
            OpServerCallDcm_MainFunction_ConditionCheckRead_DataServices_DID_37FF_ReadProtocolData: operation=DataServices_DID_37FF_ReadProtocolData.ConditionCheckRead
            OpServerCallDcm_MainFunction_ReadData_DataServices_DID_F18C_EcuSerialNumber: operation=DataServices_DID_F18C_EcuSerialNumber.ReadData
            OpServerCallDcm_MainFunction_ReadData_DataServices_DID_2540_MileKmEeprom: operation=DataServices_DID_2540_MileKmEeprom.ReadData
            OpServerCallDcm_MainFunction_ConditionCheckRead_DataServices_DID_2540_MileKmEeprom: operation=DataServices_DID_2540_MileKmEeprom.ConditionCheckRead
            OpServerCallDcm_MainFunction_ReadData_DataServices_DID_F101_SvkAktuell: operation=DataServices_DID_F101_SvkAktuell.ReadData
            OpServerCallDcm_MainFunction_ConditionCheckRead_DataServices_DID_F101_SvkAktuell: operation=DataServices_DID_F101_SvkAktuell.ConditionCheckRead
            OpServerCallDcm_MainFunction_ReadData_DataServices_DID_1701_Systemzeit: operation=DataServices_DID_1701_Systemzeit.ReadData
            OpServerCallDcm_MainFunction_ReadData_DataServices_DID_1723_DmIsDtcActiveResponse: operation=DataServices_DID_1723_DmIsDtcActiveResponse.ReadData
            OpServerCallDcm_MainFunction_ReadDataLength_DataServices_DID_1723_DmIsDtcActiveResponse: operation=DataServices_DID_1723_DmIsDtcActiveResponse.ReadDataLength
            OpServerCallDcm_MainFunction_ReadData_DataServices_DID_100E_ExtendedEnergySavingState: operation=DataServices_DID_100E_ExtendedEnergySavingState.ReadData
            OpServerCallDcm_MainFunction_ReadData_DataServices_DID_2504_FlashTimingParameter: operation=DataServices_DID_2504_FlashTimingParameter.ReadData
            OpServerCallDcm_MainFunction_ReadData_DataServices_DID_DB99_EpsMomentensensor: operation=DataServices_DID_DB99_EpsMomentensensor.ReadData
            OpServerCallDcm_MainFunction_ConditionCheckRead_DataServices_DID_DB99_EpsMomentensensor: operation=DataServices_DID_DB99_EpsMomentensensor.ConditionCheckRead
            OpServerCallDcm_MainFunction_ReadData_DataServices_DID_DB5A_EpsLenkwinkelsensorKalibrierung: operation=DataServices_DID_DB5A_EpsLenkwinkelsensorKalibrierung.ReadData
            OpServerCallDcm_MainFunction_ConditionCheckRead_DataServices_DID_DB5A_EpsLenkwinkelsensorKalibrierung: operation=DataServices_DID_DB5A_EpsLenkwinkelsensorKalibrierung.ConditionCheckRead
            OpServerCallDcm_MainFunction_WriteData_DataServices_DID_DB5A_EpsLenkwinkelsensorKalibrierung: operation=DataServices_DID_DB5A_EpsLenkwinkelsensorKalibrierung.WriteData
            OpServerCallDcm_MainFunction_ReadData_DataServices_DID_1000_Pruefstempel: operation=DataServices_DID_1000_Pruefstempel.ReadData
            OpServerCallDcm_MainFunction_ConditionCheckRead_DataServices_DID_1000_Pruefstempel: operation=DataServices_DID_1000_Pruefstempel.ConditionCheckRead
            OpServerCallDcm_MainFunction_WriteData_DataServices_DID_1000_Pruefstempel: operation=DataServices_DID_1000_Pruefstempel.WriteData
            OpServerCallDcm_MainFunction_ReadData_DataServices_DID_F18A_SystemSupplierIdentifier: operation=DataServices_DID_F18A_SystemSupplierIdentifier.ReadData
            OpServerCallDcm_MainFunction_ConditionCheckRead_DataServices_DID_F18A_SystemSupplierIdentifier: operation=DataServices_DID_F18A_SystemSupplierIdentifier.ConditionCheckRead
            OpServerCallDcm_MainFunction_ReadData_DataServices_DID_100A_EnergySavingState: operation=DataServices_DID_100A_EnergySavingState.ReadData
            OpServerCallDcm_MainFunction_ReadData_DataServices_DID_DB57_EpsRitzelwinkelsensor: operation=DataServices_DID_DB57_EpsRitzelwinkelsensor.ReadData
            OpServerCallDcm_MainFunction_ConditionCheckRead_DataServices_DID_DB57_EpsRitzelwinkelsensor: operation=DataServices_DID_DB57_EpsRitzelwinkelsensor.ConditionCheckRead
            OpServerCallDcm_MainFunction_ReadData_DataServices_DID_F150_SgbdIdx: operation=DataServices_DID_F150_SgbdIdx.ReadData
            OpServerCallDcm_MainFunction_ReadData_DataServices_DID_DB3C_StatusFzgBordnetz: operation=DataServices_DID_DB3C_StatusFzgBordnetz.ReadData
            OpServerCallDcm_MainFunction_ConditionCheckRead_DataServices_DID_DB3C_StatusFzgBordnetz: operation=DataServices_DID_DB3C_StatusFzgBordnetz.ConditionCheckRead
            OpServerCallDcm_MainFunction_ReadData_DataServices_DID_F152_Readhwmodificationindex: operation=DataServices_DID_F152_Readhwmodificationindex.ReadData
            OpServerCallDcm_MainFunction_WriteData_DataServices_DID_F15A_WdbiFp: operation=DataServices_DID_F15A_WdbiFp.WriteData
            OpServerCallDcm_MainFunction_ReadData_DataServices_DID_DFDD_GelernterZahnstangenweg: operation=DataServices_DID_DFDD_GelernterZahnstangenweg.ReadData
            OpServerCallDcm_MainFunction_ConditionCheckRead_DataServices_DID_DFDD_GelernterZahnstangenweg: operation=DataServices_DID_DFDD_GelernterZahnstangenweg.ConditionCheckRead
            OpServerCallDcm_MainFunction_ReadData_DataServices_DID_2507_SwfkDeleteSupported: operation=DataServices_DID_2507_SwfkDeleteSupported.ReadData
            OpServerCallDcm_MainFunction_ConditionCheckRead_DataServices_DID_2507_SwfkDeleteSupported: operation=DataServices_DID_2507_SwfkDeleteSupported.ConditionCheckRead
            OpServerCallDcm_MainFunction_ReadData_DataServices_DID_F100_ReadActiveSessionState: operation=DataServices_DID_F100_ReadActiveSessionState.ReadData
            OpServerCallDcm_MainFunction_ConditionCheckRead_DataServices_DID_F100_ReadActiveSessionState: operation=DataServices_DID_F100_ReadActiveSessionState.ConditionCheckRead
            OpServerCallDcm_MainFunction_ReadData_DataServices_DID_250B_ReadSwRevision: operation=DataServices_DID_250B_ReadSwRevision.ReadData
            OpServerCallDcm_MainFunction_ConditionCheckRead_DataServices_DID_250B_ReadSwRevision: operation=DataServices_DID_250B_ReadSwRevision.ConditionCheckRead
            OpServerCallDcm_MainFunction_ReadData_DataServices_DID_F102_SvkSysSupplier: operation=DataServices_DID_F102_SvkSysSupplier.ReadData
            OpServerCallDcm_MainFunction_ConditionCheckRead_DataServices_DID_F102_SvkSysSupplier: operation=DataServices_DID_F102_SvkSysSupplier.ConditionCheckRead
            OpServerCallDcm_MainFunction_ReadData_DataServices_DID_2541_StatusCalcvn: operation=DataServices_DID_2541_StatusCalcvn.ReadData
            OpServerCallDcm_MainFunction_ReadData_DataServices_DID_DC77_EpsZahnstangenmitte: operation=DataServices_DID_DC77_EpsZahnstangenmitte.ReadData
            OpServerCallDcm_MainFunction_ConditionCheckRead_DataServices_DID_DC77_EpsZahnstangenmitte: operation=DataServices_DID_DC77_EpsZahnstangenmitte.ConditionCheckRead
            OpServerCallDcm_MainFunction_ReadData_DataServices_DID_F103_SvkWerk: operation=DataServices_DID_F103_SvkWerk.ReadData
            OpServerCallDcm_MainFunction_ConditionCheckRead_DataServices_DID_F103_SvkWerk: operation=DataServices_DID_F103_SvkWerk.ConditionCheckRead
            OpServerCallDcm_MainFunction_ReadData_DataServices_DID_2503_ProgrammingCounterMaxValue: operation=DataServices_DID_2503_ProgrammingCounterMaxValue.ReadData
            OpServerCallDcm_MainFunction_ConditionCheckRead_DataServices_DID_2503_ProgrammingCounterMaxValue: operation=DataServices_DID_2503_ProgrammingCounterMaxValue.ConditionCheckRead
            OpServerCallDcm_MainFunction_ReadData_DataServices_DID_F18B_Herstelldatum: operation=DataServices_DID_F18B_Herstelldatum.ReadData
            OpServerCallDcm_MainFunction_ReadData_DataServices_DID_37FE_Cps: operation=DataServices_DID_37FE_Cps.ReadData
            OpServerCallDcm_MainFunction_ConditionCheckRead_DataServices_DID_37FE_Cps: operation=DataServices_DID_37FE_Cps.ConditionCheckRead
            OpServerCallDcm_MainFunction_ReadData_DataServices_DID_2502_ProgrammingCounter: operation=DataServices_DID_2502_ProgrammingCounter.ReadData
            OpServerCallDcm_MainFunction_WriteData_DataServices_DID_2503_ProgrammingCounterMaxValue: operation=DataServices_DID_2503_ProgrammingCounterMaxValue.WriteData
  swc implementation DcmImplementation: programming-language=C, behavior=DcmInternalBehavior
